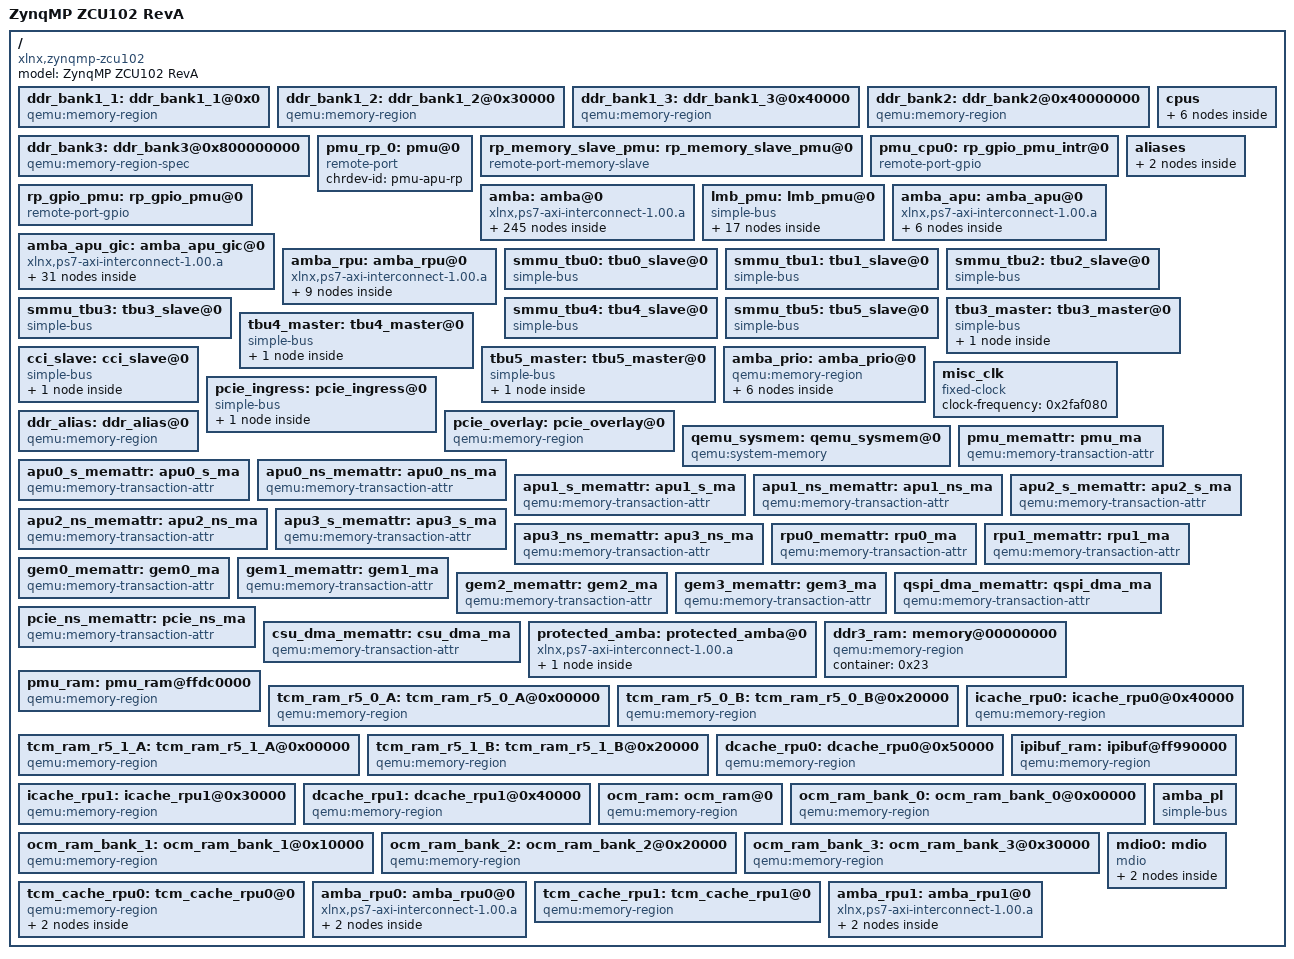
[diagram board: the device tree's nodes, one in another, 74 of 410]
/dts-v1/;

/ {
	#address-cells = < 0x02 >;
	#size-cells = < 0x01 >;
	model = "ZynqMP ZCU102 RevA";
	compatible = "xlnx,zynqmp-zcu102", "xlnx,zynqmp";

	ddr_bank1_1: ddr_bank1_1@0x0 {
		compatible = "qemu:memory-region";
		container = < 0x01 >;
		qemu,ram = < 0x02 >;
		reg = < 0x00 0x00 0x30000 >;
	};

	ddr_bank1_2: ddr_bank1_2@0x30000 {
		compatible = "qemu:memory-region";
		container = < 0x01 >;
		qemu,ram = < 0x02 >;
		reg = < 0x00 0x30000 0x10000 >;
		phandle = < 0x83 >;
	};

	ddr_bank1_3: ddr_bank1_3@0x40000 {
		compatible = "qemu:memory-region";
		container = < 0x01 >;
		qemu,ram = < 0x02 >;
		reg = < 0x00 0x40000 0x3ffc0000 >;
	};

	ddr_bank2: ddr_bank2@0x40000000 {
		compatible = "qemu:memory-region";
		container = < 0x01 >;
		qemu,ram = < 0x02 >;
		reg = < 0x00 0x40000000 0x40000000 >;
	};

	ddr_bank3: ddr_bank3@0x800000000 {
		compatible = "qemu:memory-region-spec";
		container = < 0x01 >;
		qemu,ram = < 0x02 >;
		reg = < 0x08 0x00 0x08 0x00 >;
	};

	pmu_rp_0: pmu@0 {
		compatible = "remote-port";
		#interrupt-cells = < 0x02 >;
		chrdev-id = "pmu-apu-rp";
		phandle = < 0x02 >;
	};

	rp_memory_slave_pmu: rp_memory_slave_pmu@0 {
		compatible = "remote-port-memory-slave";
		remote-ports = < 0x02 0x00 >;
		mr = < 0x03 >;
	};

	pmu_cpu0: rp_gpio_pmu_intr@0 {
		#interrupt-cells = < 0x01 >;
		compatible = "remote-port-gpio";
		remote-ports = < 0x02 0x01 >;
		interrupt-controller;
		num-gpios = < 0x01 >;
		phandle = < 0x61 >;
	};

	rp_gpio_pmu: rp_gpio_pmu@0 {
		compatible = "remote-port-gpio";
		remote-ports = < 0x02 0x02 >;
		gpio-controller;
		#gpio-cells = < 0x01 >;
		num-gpios = < 0x04 >;
		gpios = < 0x04 0x00 0x05 0x02 0x04 0x03 >;
		phandle = < 0x14 >;
	};

	amba: amba@0 {
		#interrupt-cells = < 0x01 >;
		compatible = "xlnx,ps7-axi-interconnect-1.00.a", "simple-bus";
		ranges;
		interrupt-map-mask = < 0x00 0x00 0xffff >;
		interrupt-map = < 0x00 0x00 0x08 0x06 0x00 0x08 0x04 >, < 0x00 0x00 0x09 0x06 0x00 0x09 0x04 >, < 0x00 0x00 0x0a 0x06 0x00 0x0a 0x04 >, < 0x00 0x00 0x0b 0x06 0x00 0x0b 0x04 >, < 0x00 0x00 0x0b 0x06 0x00 0x0b 0x04 >, < 0x00 0x00 0x0b 0x06 0x00 0x0b 0x04 >, < 0x00 0x00 0x0b 0x06 0x00 0x0b 0x04 >, < 0x00 0x00 0x0b 0x06 0x00 0x0b 0x04 >, < 0x00 0x00 0x0b 0x06 0x00 0x0b 0x04 >, < 0x00 0x00 0x0b 0x06 0x00 0x0b 0x04 >, < 0x00 0x00 0x0b 0x06 0x00 0x0b 0x04 >, < 0x00 0x00 0x0b 0x06 0x00 0x0b 0x04 >, < 0x00 0x00 0x0b 0x06 0x00 0x0b 0x04 >, < 0x00 0x00 0x0b 0x06 0x00 0x0b 0x04 >, < 0x00 0x00 0x0b 0x06 0x00 0x0b 0x04 >, < 0x00 0x00 0x0b 0x06 0x00 0x0b 0x04 >, < 0x00 0x00 0x0b 0x06 0x00 0x0b 0x04 >, < 0x00 0x00 0x0c 0x06 0x00 0x0c 0x04 >, < 0x00 0x00 0x0d 0x06 0x00 0x0d 0x04 >, < 0x00 0x00 0x0e 0x06 0x00 0x0e 0x04 >, < 0x00 0x00 0x0f 0x06 0x00 0x0f 0x04 >, < 0x00 0x00 0x10 0x06 0x00 0x10 0x04 >, < 0x00 0x00 0x11 0x06 0x00 0x11 0x04 >, < 0x00 0x00 0x12 0x06 0x00 0x12 0x04 >, < 0x00 0x00 0x13 0x06 0x00 0x13 0x04 >, < 0x00 0x00 0x14 0x06 0x00 0x14 0x04 >, < 0x00 0x00 0x15 0x06 0x00 0x15 0x04 >, < 0x00 0x00 0x16 0x06 0x00 0x16 0x04 >, < 0x00 0x00 0x17 0x06 0x00 0x17 0x04 >, < 0x00 0x00 0x18 0x06 0x00 0x18 0x04 >, < 0x00 0x00 0x19 0x06 0x00 0x19 0x04 >, < 0x00 0x00 0x19 0x06 0x00 0x19 0x04 >, < 0x00 0x00 0x1a 0x06 0x00 0x1a 0x04 >, < 0x00 0x00 0x1b 0x06 0x00 0x1b 0x04 >, < 0x00 0x00 0x1c 0x06 0x00 0x1c 0x04 >, < 0x00 0x00 0x1d 0x06 0x00 0x1d 0x04 >, < 0x00 0x00 0x1e 0x06 0x00 0x1e 0x04 >, < 0x00 0x00 0x1f 0x06 0x00 0x1f 0x04 >, < 0x00 0x00 0x20 0x06 0x00 0x20 0x04 >, < 0x00 0x00 0x21 0x06 0x00 0x21 0x04 >, < 0x00 0x00 0x22 0x06 0x00 0x22 0x04 >, < 0x00 0x00 0x23 0x06 0x00 0x23 0x04 >, < 0x00 0x00 0x24 0x06 0x00 0x24 0x04 >, < 0x00 0x00 0x25 0x06 0x00 0x25 0x04 >, < 0x00 0x00 0x26 0x06 0x00 0x26 0x04 >, < 0x00 0x00 0x27 0x06 0x00 0x27 0x04 >, < 0x00 0x00 0x28 0x06 0x00 0x28 0x04 >, < 0x00 0x00 0x29 0x06 0x00 0x29 0x04 >, < 0x00 0x00 0x2a 0x06 0x00 0x2a 0x04 >, < 0x00 0x00 0x2b 0x06 0x00 0x2b 0x04 >, < 0x00 0x00 0x2c 0x06 0x00 0x2c 0x04 >, < 0x00 0x00 0x2d 0x06 0x00 0x2d 0x04 >, < 0x00 0x00 0x2e 0x06 0x00 0x2e 0x04 >, < 0x00 0x00 0x2f 0x06 0x00 0x2f 0x04 >, < 0x00 0x00 0x30 0x06 0x00 0x30 0x04 >, < 0x00 0x00 0x31 0x06 0x00 0x31 0x04 >, < 0x00 0x00 0x32 0x06 0x00 0x32 0x04 >, < 0x00 0x00 0x33 0x06 0x00 0x33 0x04 >, < 0x00 0x00 0x34 0x06 0x00 0x34 0x04 >, < 0x00 0x00 0x35 0x06 0x00 0x35 0x04 >, < 0x00 0x00 0x36 0x06 0x00 0x36 0x04 >, < 0x00 0x00 0x37 0x06 0x00 0x37 0x04 >, < 0x00 0x00 0x38 0x06 0x00 0x38 0x04 >, < 0x00 0x00 0x39 0x06 0x00 0x39 0x04 >, < 0x00 0x00 0x3a 0x06 0x00 0x3a 0x04 >, < 0x00 0x00 0x3b 0x06 0x00 0x3b 0x04 >, < 0x00 0x00 0x3c 0x06 0x00 0x3c 0x04 >, < 0x00 0x00 0x3d 0x06 0x00 0x3d 0x04 >, < 0x00 0x00 0x3e 0x06 0x00 0x3e 0x04 >, < 0x00 0x00 0x3f 0x06 0x00 0x3f 0x04 >, < 0x00 0x00 0x40 0x06 0x00 0x40 0x04 >, < 0x00 0x00 0x41 0x06 0x00 0x41 0x04 >, < 0x00 0x00 0x42 0x06 0x00 0x42 0x04 >, < 0x00 0x00 0x43 0x06 0x00 0x43 0x04 >, < 0x00 0x00 0x44 0x06 0x00 0x44 0x04 >, < 0x00 0x00 0x45 0x06 0x00 0x45 0x04 >, < 0x00 0x00 0x46 0x06 0x00 0x46 0x04 >, < 0x00 0x00 0x47 0x06 0x00 0x47 0x04 >, < 0x00 0x00 0x48 0x06 0x00 0x48 0x04 >, < 0x00 0x00 0x49 0x06 0x00 0x49 0x04 >, < 0x00 0x00 0x4a 0x06 0x00 0x4a 0x04 >, < 0x00 0x00 0x4b 0x06 0x00 0x4b 0x04 >, < 0x00 0x00 0x4c 0x06 0x00 0x4c 0x04 >, < 0x00 0x00 0x4d 0x06 0x00 0x4d 0x04 >, < 0x00 0x00 0x4e 0x06 0x00 0x4e 0x04 >, < 0x00 0x00 0x4f 0x06 0x00 0x4f 0x04 >, < 0x00 0x00 0x50 0x06 0x00 0x50 0x04 >, < 0x00 0x00 0x51 0x06 0x00 0x51 0x04 >, < 0x00 0x00 0x52 0x06 0x00 0x52 0x04 >, < 0x00 0x00 0x53 0x06 0x00 0x53 0x04 >, < 0x00 0x00 0x54 0x06 0x00 0x54 0x04 >, < 0x00 0x00 0x55 0x06 0x00 0x55 0x04 >, < 0x00 0x00 0x56 0x06 0x00 0x56 0x04 >, < 0x00 0x00 0x57 0x06 0x00 0x57 0x04 >, < 0x00 0x00 0x58 0x06 0x00 0x58 0x04 >, < 0x00 0x00 0x58 0x06 0x00 0x58 0x04 >, < 0x00 0x00 0x59 0x06 0x00 0x59 0x04 >, < 0x00 0x00 0x5a 0x06 0x00 0x5a 0x04 >, < 0x00 0x00 0x5b 0x06 0x00 0x5b 0x04 >, < 0x00 0x00 0x5c 0x06 0x00 0x5c 0x04 >, < 0x00 0x00 0x5d 0x06 0x00 0x5d 0x04 >, < 0x00 0x00 0x5e 0x06 0x00 0x5e 0x04 >, < 0x00 0x00 0x5f 0x06 0x00 0x5f 0x04 >, < 0x00 0x00 0x60 0x06 0x00 0x60 0x04 >, < 0x00 0x00 0x68 0x06 0x00 0x68 0x04 >, < 0x00 0x00 0x69 0x06 0x00 0x69 0x04 >, < 0x00 0x00 0x6a 0x06 0x00 0x6a 0x04 >, < 0x00 0x00 0x6b 0x06 0x00 0x6b 0x04 >, < 0x00 0x00 0x6c 0x06 0x00 0x6c 0x04 >, < 0x00 0x00 0x6d 0x06 0x00 0x6d 0x04 >, < 0x00 0x00 0x6e 0x06 0x00 0x6e 0x04 >, < 0x00 0x00 0x6f 0x06 0x00 0x6f 0x04 >, < 0x00 0x00 0x70 0x06 0x00 0x70 0x04 >, < 0x00 0x00 0x71 0x06 0x00 0x71 0x04 >, < 0x00 0x00 0x72 0x06 0x00 0x72 0x04 >, < 0x00 0x00 0x73 0x06 0x00 0x73 0x04 >, < 0x00 0x00 0x74 0x06 0x00 0x74 0x04 >, < 0x00 0x00 0x75 0x06 0x00 0x75 0x04 >, < 0x00 0x00 0x76 0x06 0x00 0x76 0x04 >, < 0x00 0x00 0x77 0x06 0x00 0x77 0x04 >, < 0x00 0x00 0x78 0x06 0x00 0x78 0x04 >, < 0x00 0x00 0x78 0x06 0x00 0x78 0x04 >, < 0x00 0x00 0x78 0x06 0x00 0x78 0x04 >, < 0x00 0x00 0x78 0x06 0x00 0x78 0x04 >, < 0x00 0x00 0x78 0x06 0x00 0x78 0x04 >, < 0x00 0x00 0x78 0x06 0x00 0x78 0x04 >, < 0x00 0x00 0x78 0x06 0x00 0x78 0x04 >, < 0x00 0x00 0x78 0x06 0x00 0x78 0x04 >, < 0x00 0x00 0x78 0x06 0x00 0x78 0x04 >, < 0x00 0x00 0x78 0x06 0x00 0x78 0x04 >, < 0x00 0x00 0x78 0x06 0x00 0x78 0x04 >, < 0x00 0x00 0x79 0x06 0x00 0x79 0x04 >, < 0x00 0x00 0x7a 0x06 0x00 0x7a 0x04 >, < 0x00 0x00 0x7b 0x06 0x00 0x7b 0x04 >, < 0x00 0x00 0x7b 0x06 0x00 0x7b 0x04 >, < 0x00 0x00 0x7c 0x06 0x00 0x7c 0x04 >, < 0x00 0x00 0x7d 0x06 0x00 0x7d 0x04 >, < 0x00 0x00 0x7e 0x06 0x00 0x7e 0x04 >, < 0x00 0x00 0x7f 0x06 0x00 0x7f 0x04 >, < 0x00 0x00 0x80 0x06 0x00 0x80 0x04 >, < 0x00 0x00 0x81 0x06 0x00 0x81 0x04 >, < 0x00 0x00 0x82 0x06 0x00 0x82 0x04 >, < 0x00 0x00 0x83 0x06 0x00 0x83 0x04 >, < 0x00 0x00 0x84 0x06 0x00 0x84 0x04 >, < 0x00 0x00 0x85 0x06 0x00 0x85 0x04 >, < 0x00 0x00 0x86 0x06 0x00 0x86 0x04 >, < 0x00 0x00 0x86 0x06 0x00 0x86 0x04 >, < 0x00 0x00 0x86 0x06 0x00 0x86 0x04 >, < 0x00 0x00 0x86 0x06 0x00 0x86 0x04 >, < 0x00 0x00 0x86 0x06 0x00 0x86 0x04 >, < 0x00 0x00 0x86 0x06 0x00 0x86 0x04 >, < 0x00 0x00 0x86 0x06 0x00 0x86 0x04 >, < 0x00 0x00 0x87 0x06 0x00 0x87 0x04 >, < 0x00 0x00 0x88 0x06 0x00 0x88 0x04 >, < 0x00 0x00 0x89 0x06 0x00 0x89 0x04 >, < 0x00 0x00 0x8a 0x06 0x00 0x8a 0x04 >, < 0x00 0x00 0x8b 0x06 0x00 0x8b 0x04 >, < 0x00 0x00 0x8c 0x06 0x00 0x8c 0x04 >, < 0x00 0x00 0x8d 0x06 0x00 0x8d 0x04 >, < 0x00 0x00 0x8e 0x06 0x00 0x8e 0x04 >, < 0x00 0x00 0x8f 0x06 0x00 0x8f 0x04 >, < 0x00 0x00 0x90 0x06 0x00 0x90 0x04 >, < 0x00 0x00 0x91 0x06 0x00 0x91 0x04 >, < 0x00 0x00 0x92 0x06 0x00 0x92 0x04 >, < 0x00 0x00 0x93 0x06 0x00 0x93 0x04 >, < 0x00 0x00 0x94 0x06 0x00 0x94 0x04 >, < 0x00 0x00 0x95 0x06 0x00 0x95 0x04 >, < 0x00 0x00 0x96 0x06 0x00 0x96 0x04 >, < 0x00 0x00 0x97 0x06 0x00 0x97 0x04 >, < 0x00 0x00 0x98 0x06 0x00 0x98 0x04 >, < 0x00 0x00 0x99 0x06 0x00 0x99 0x04 >, < 0x00 0x00 0x9a 0x06 0x00 0x9a 0x04 >, < 0x00 0x00 0x9b 0x06 0x00 0x9b 0x04 >, < 0x00 0x00 0x08 0x07 0x00 0x08 0x04 >, < 0x00 0x00 0x09 0x07 0x00 0x09 0x04 >, < 0x00 0x00 0x0a 0x07 0x00 0x0a 0x04 >, < 0x00 0x00 0x0b 0x07 0x00 0x0b 0x04 >, < 0x00 0x00 0x0b 0x07 0x00 0x0b 0x04 >, < 0x00 0x00 0x0b 0x07 0x00 0x0b 0x04 >, < 0x00 0x00 0x0b 0x07 0x00 0x0b 0x04 >, < 0x00 0x00 0x0b 0x07 0x00 0x0b 0x04 >, < 0x00 0x00 0x0b 0x07 0x00 0x0b 0x04 >, < 0x00 0x00 0x0b 0x07 0x00 0x0b 0x04 >, < 0x00 0x00 0x0b 0x07 0x00 0x0b 0x04 >, < 0x00 0x00 0x0b 0x07 0x00 0x0b 0x04 >, < 0x00 0x00 0x0b 0x07 0x00 0x0b 0x04 >, < 0x00 0x00 0x0b 0x07 0x00 0x0b 0x04 >, < 0x00 0x00 0x0b 0x07 0x00 0x0b 0x04 >, < 0x00 0x00 0x0b 0x07 0x00 0x0b 0x04 >, < 0x00 0x00 0x0b 0x07 0x00 0x0b 0x04 >, < 0x00 0x00 0x0c 0x07 0x00 0x0c 0x04 >, < 0x00 0x00 0x0d 0x07 0x00 0x0d 0x04 >, < 0x00 0x00 0x0e 0x07 0x00 0x0e 0x04 >, < 0x00 0x00 0x0f 0x07 0x00 0x0f 0x04 >, < 0x00 0x00 0x10 0x07 0x00 0x10 0x04 >, < 0x00 0x00 0x11 0x07 0x00 0x11 0x04 >, < 0x00 0x00 0x12 0x07 0x00 0x12 0x04 >, < 0x00 0x00 0x13 0x07 0x00 0x13 0x04 >, < 0x00 0x00 0x14 0x07 0x00 0x14 0x04 >, < 0x00 0x00 0x15 0x07 0x00 0x15 0x04 >, < 0x00 0x00 0x16 0x07 0x00 0x16 0x04 >, < 0x00 0x00 0x17 0x07 0x00 0x17 0x04 >, < 0x00 0x00 0x18 0x07 0x00 0x18 0x04 >, < 0x00 0x00 0x19 0x07 0x00 0x19 0x04 >, < 0x00 0x00 0x19 0x07 0x00 0x19 0x04 >, < 0x00 0x00 0x1a 0x07 0x00 0x1a 0x04 >, < 0x00 0x00 0x1b 0x07 0x00 0x1b 0x04 >, < 0x00 0x00 0x1c 0x07 0x00 0x1c 0x04 >, < 0x00 0x00 0x1d 0x07 0x00 0x1d 0x04 >, < 0x00 0x00 0x1e 0x07 0x00 0x1e 0x04 >, < 0x00 0x00 0x1f 0x07 0x00 0x1f 0x04 >, < 0x00 0x00 0x20 0x07 0x00 0x20 0x04 >, < 0x00 0x00 0x21 0x07 0x00 0x21 0x04 >, < 0x00 0x00 0x22 0x07 0x00 0x22 0x04 >, < 0x00 0x00 0x23 0x07 0x00 0x23 0x04 >, < 0x00 0x00 0x24 0x07 0x00 0x24 0x04 >, < 0x00 0x00 0x25 0x07 0x00 0x25 0x04 >, < 0x00 0x00 0x26 0x07 0x00 0x26 0x04 >, < 0x00 0x00 0x27 0x07 0x00 0x27 0x04 >, < 0x00 0x00 0x28 0x07 0x00 0x28 0x04 >, < 0x00 0x00 0x29 0x07 0x00 0x29 0x04 >, < 0x00 0x00 0x2a 0x07 0x00 0x2a 0x04 >, < 0x00 0x00 0x2b 0x07 0x00 0x2b 0x04 >, < 0x00 0x00 0x2c 0x07 0x00 0x2c 0x04 >, < 0x00 0x00 0x2d 0x07 0x00 0x2d 0x04 >, < 0x00 0x00 0x2e 0x07 0x00 0x2e 0x04 >, < 0x00 0x00 0x2f 0x07 0x00 0x2f 0x04 >, < 0x00 0x00 0x30 0x07 0x00 0x30 0x04 >, < 0x00 0x00 0x31 0x07 0x00 0x31 0x04 >, < 0x00 0x00 0x32 0x07 0x00 0x32 0x04 >, < 0x00 0x00 0x33 0x07 0x00 0x33 0x04 >, < 0x00 0x00 0x34 0x07 0x00 0x34 0x04 >, < 0x00 0x00 0x35 0x07 0x00 0x35 0x04 >, < 0x00 0x00 0x36 0x07 0x00 0x36 0x04 >, < 0x00 0x00 0x37 0x07 0x00 0x37 0x04 >, < 0x00 0x00 0x38 0x07 0x00 0x38 0x04 >, < 0x00 0x00 0x39 0x07 0x00 0x39 0x04 >, < 0x00 0x00 0x3a 0x07 0x00 0x3a 0x04 >, < 0x00 0x00 0x3b 0x07 0x00 0x3b 0x04 >, < 0x00 0x00 0x3c 0x07 0x00 0x3c 0x04 >, < 0x00 0x00 0x3d 0x07 0x00 0x3d 0x04 >, < 0x00 0x00 0x3e 0x07 0x00 0x3e 0x04 >, < 0x00 0x00 0x3f 0x07 0x00 0x3f 0x04 >, < 0x00 0x00 0x40 0x07 0x00 0x40 0x04 >, < 0x00 0x00 0x41 0x07 0x00 0x41 0x04 >, < 0x00 0x00 0x42 0x07 0x00 0x42 0x04 >, < 0x00 0x00 0x43 0x07 0x00 0x43 0x04 >, < 0x00 0x00 0x44 0x07 0x00 0x44 0x04 >, < 0x00 0x00 0x45 0x07 0x00 0x45 0x04 >, < 0x00 0x00 0x46 0x07 0x00 0x46 0x04 >, < 0x00 0x00 0x47 0x07 0x00 0x47 0x04 >, < 0x00 0x00 0x48 0x07 0x00 0x48 0x04 >, < 0x00 0x00 0x49 0x07 0x00 0x49 0x04 >, < 0x00 0x00 0x4a 0x07 0x00 0x4a 0x04 >, < 0x00 0x00 0x4b 0x07 0x00 0x4b 0x04 >, < 0x00 0x00 0x4c 0x07 0x00 0x4c 0x04 >, < 0x00 0x00 0x4d 0x07 0x00 0x4d 0x04 >, < 0x00 0x00 0x4e 0x07 0x00 0x4e 0x04 >, < 0x00 0x00 0x4f 0x07 0x00 0x4f 0x04 >, < 0x00 0x00 0x50 0x07 0x00 0x50 0x04 >, < 0x00 0x00 0x51 0x07 0x00 0x51 0x04 >, < 0x00 0x00 0x52 0x07 0x00 0x52 0x04 >, < 0x00 0x00 0x53 0x07 0x00 0x53 0x04 >, < 0x00 0x00 0x54 0x07 0x00 0x54 0x04 >, < 0x00 0x00 0x55 0x07 0x00 0x55 0x04 >, < 0x00 0x00 0x56 0x07 0x00 0x56 0x04 >, < 0x00 0x00 0x57 0x07 0x00 0x57 0x04 >, < 0x00 0x00 0x58 0x07 0x00 0x58 0x04 >, < 0x00 0x00 0x58 0x07 0x00 0x58 0x04 >, < 0x00 0x00 0x59 0x07 0x00 0x59 0x04 >, < 0x00 0x00 0x5a 0x07 0x00 0x5a 0x04 >, < 0x00 0x00 0x5b 0x07 0x00 0x5b 0x04 >, < 0x00 0x00 0x5c 0x07 0x00 0x5c 0x04 >, < 0x00 0x00 0x5d 0x07 0x00 0x5d 0x04 >, < 0x00 0x00 0x5e 0x07 0x00 0x5e 0x04 >, < 0x00 0x00 0x5f 0x07 0x00 0x5f 0x04 >, < 0x00 0x00 0x60 0x07 0x00 0x60 0x04 >, < 0x00 0x00 0x68 0x07 0x00 0x68 0x04 >, < 0x00 0x00 0x69 0x07 0x00 0x69 0x04 >, < 0x00 0x00 0x6a 0x07 0x00 0x6a 0x04 >, < 0x00 0x00 0x6b 0x07 0x00 0x6b 0x04 >, < 0x00 0x00 0x6c 0x07 0x00 0x6c 0x04 >, < 0x00 0x00 0x6d 0x07 0x00 0x6d 0x04 >, < 0x00 0x00 0x6e 0x07 0x00 0x6e 0x04 >, < 0x00 0x00 0x6f 0x07 0x00 0x6f 0x04 >, < 0x00 0x00 0x70 0x07 0x00 0x70 0x04 >, < 0x00 0x00 0x71 0x07 0x00 0x71 0x04 >, < 0x00 0x00 0x72 0x07 0x00 0x72 0x04 >, < 0x00 0x00 0x73 0x07 0x00 0x73 0x04 >, < 0x00 0x00 0x74 0x07 0x00 0x74 0x04 >, < 0x00 0x00 0x75 0x07 0x00 0x75 0x04 >, < 0x00 0x00 0x76 0x07 0x00 0x76 0x04 >, < 0x00 0x00 0x77 0x07 0x00 0x77 0x04 >, < 0x00 0x00 0x78 0x07 0x00 0x78 0x04 >, < 0x00 0x00 0x78 0x07 0x00 0x78 0x04 >, < 0x00 0x00 0x78 0x07 0x00 0x78 0x04 >, < 0x00 0x00 0x78 0x07 0x00 0x78 0x04 >, < 0x00 0x00 0x78 0x07 0x00 0x78 0x04 >, < 0x00 0x00 0x78 0x07 0x00 0x78 0x04 >, < 0x00 0x00 0x78 0x07 0x00 0x78 0x04 >, < 0x00 0x00 0x78 0x07 0x00 0x78 0x04 >, < 0x00 0x00 0x78 0x07 0x00 0x78 0x04 >, < 0x00 0x00 0x78 0x07 0x00 0x78 0x04 >, < 0x00 0x00 0x78 0x07 0x00 0x78 0x04 >, < 0x00 0x00 0x79 0x07 0x00 0x79 0x04 >, < 0x00 0x00 0x7a 0x07 0x00 0x7a 0x04 >, < 0x00 0x00 0x7b 0x07 0x00 0x7b 0x04 >, < 0x00 0x00 0x7b 0x07 0x00 0x7b 0x04 >, < 0x00 0x00 0x7c 0x07 0x00 0x7c 0x04 >, < 0x00 0x00 0x7d 0x07 0x00 0x7d 0x04 >, < 0x00 0x00 0x7e 0x07 0x00 0x7e 0x04 >, < 0x00 0x00 0x7f 0x07 0x00 0x7f 0x04 >, < 0x00 0x00 0x80 0x07 0x00 0x80 0x04 >, < 0x00 0x00 0x81 0x07 0x00 0x81 0x04 >, < 0x00 0x00 0x82 0x07 0x00 0x82 0x04 >, < 0x00 0x00 0x83 0x07 0x00 0x83 0x04 >, < 0x00 0x00 0x84 0x07 0x00 0x84 0x04 >, < 0x00 0x00 0x85 0x07 0x00 0x85 0x04 >, < 0x00 0x00 0x86 0x07 0x00 0x86 0x04 >, < 0x00 0x00 0x86 0x07 0x00 0x86 0x04 >, < 0x00 0x00 0x86 0x07 0x00 0x86 0x04 >, < 0x00 0x00 0x86 0x07 0x00 0x86 0x04 >, < 0x00 0x00 0x86 0x07 0x00 0x86 0x04 >, < 0x00 0x00 0x86 0x07 0x00 0x86 0x04 >, < 0x00 0x00 0x86 0x07 0x00 0x86 0x04 >, < 0x00 0x00 0x87 0x07 0x00 0x87 0x04 >, < 0x00 0x00 0x88 0x07 0x00 0x88 0x04 >, < 0x00 0x00 0x89 0x07 0x00 0x89 0x04 >, < 0x00 0x00 0x8a 0x07 0x00 0x8a 0x04 >, < 0x00 0x00 0x8b 0x07 0x00 0x8b 0x04 >, < 0x00 0x00 0x8c 0x07 0x00 0x8c 0x04 >, < 0x00 0x00 0x8d 0x07 0x00 0x8d 0x04 >, < 0x00 0x00 0x8e 0x07 0x00 0x8e 0x04 >, < 0x00 0x00 0x8f 0x07 0x00 0x8f 0x04 >, < 0x00 0x00 0x90 0x07 0x00 0x90 0x04 >, < 0x00 0x00 0x91 0x07 0x00 0x91 0x04 >, < 0x00 0x00 0x92 0x07 0x00 0x92 0x04 >, < 0x00 0x00 0x93 0x07 0x00 0x93 0x04 >, < 0x00 0x00 0x94 0x07 0x00 0x94 0x04 >, < 0x00 0x00 0x95 0x07 0x00 0x95 0x04 >, < 0x00 0x00 0x96 0x07 0x00 0x96 0x04 >, < 0x00 0x00 0x97 0x07 0x00 0x97 0x04 >, < 0x00 0x00 0x98 0x07 0x00 0x98 0x04 >, < 0x00 0x00 0x99 0x07 0x00 0x99 0x04 >, < 0x00 0x00 0x9a 0x07 0x00 0x9a 0x04 >, < 0x00 0x00 0x9b 0x07 0x00 0x9b 0x04 >, < 0x00 0x00 0x08 0x08 0x00 0x08 0x04 >, < 0x00 0x00 0x09 0x08 0x00 0x09 0x04 >, < 0x00 0x00 0x0a 0x08 0x00 0x0a 0x04 >, < 0x00 0x00 0x0b 0x08 0x00 0x0b 0x04 >, < 0x00 0x00 0x0b 0x08 0x00 0x0b 0x04 >, < 0x00 0x00 0x0b 0x08 0x00 0x0b 0x04 >, < 0x00 0x00 0x0b 0x08 0x00 0x0b 0x04 >, < 0x00 0x00 0x0b 0x08 0x00 0x0b 0x04 >, < 0x00 0x00 0x0b 0x08 0x00 0x0b 0x04 >, < 0x00 0x00 0x0b 0x08 0x00 0x0b 0x04 >, < 0x00 0x00 0x0b 0x08 0x00 0x0b 0x04 >, < 0x00 0x00 0x0b 0x08 0x00 0x0b 0x04 >, < 0x00 0x00 0x0b 0x08 0x00 0x0b 0x04 >, < 0x00 0x00 0x0b 0x08 0x00 0x0b 0x04 >, < 0x00 0x00 0x0b 0x08 0x00 0x0b 0x04 >, < 0x00 0x00 0x0b 0x08 0x00 0x0b 0x04 >, < 0x00 0x00 0x0b 0x08 0x00 0x0b 0x04 >, < 0x00 0x00 0x0c 0x08 0x00 0x0c 0x04 >, < 0x00 0x00 0x0d 0x08 0x00 0x0d 0x04 >, < 0x00 0x00 0x0e 0x08 0x00 0x0e 0x04 >, < 0x00 0x00 0x0f 0x08 0x00 0x0f 0x04 >, < 0x00 0x00 0x10 0x08 0x00 0x10 0x04 >, < 0x00 0x00 0x11 0x08 0x00 0x11 0x04 >, < 0x00 0x00 0x12 0x08 0x00 0x12 0x04 >, < 0x00 0x00 0x13 0x08 0x00 0x13 0x04 >, < 0x00 0x00 0x14 0x08 0x00 0x14 0x04 >, < 0x00 0x00 0x15 0x08 0x00 0x15 0x04 >, < 0x00 0x00 0x16 0x08 0x00 0x16 0x04 >, < 0x00 0x00 0x17 0x08 0x00 0x17 0x04 >, < 0x00 0x00 0x18 0x08 0x00 0x18 0x04 >, < 0x00 0x00 0x19 0x08 0x00 0x19 0x04 >, < 0x00 0x00 0x19 0x08 0x00 0x19 0x04 >, < 0x00 0x00 0x1a 0x08 0x00 0x1a 0x04 >, < 0x00 0x00 0x1b 0x08 0x00 0x1b 0x04 >, < 0x00 0x00 0x1c 0x08 0x00 0x1c 0x04 >, < 0x00 0x00 0x1d 0x08 0x00 0x1d 0x04 >, < 0x00 0x00 0x1e 0x08 0x00 0x1e 0x04 >, < 0x00 0x00 0x1f 0x08 0x00 0x1f 0x04 >, < 0x00 0x00 0x20 0x08 0x00 0x20 0x04 >, < 0x00 0x00 0x21 0x08 0x00 0x21 0x04 >, < 0x00 0x00 0x22 0x08 0x00 0x22 0x04 >, < 0x00 0x00 0x23 0x08 0x00 0x23 0x04 >, < 0x00 0x00 0x24 0x08 0x00 0x24 0x04 >, < 0x00 0x00 0x25 0x08 0x00 0x25 0x04 >, < 0x00 0x00 0x26 0x08 0x00 0x26 0x04 >, < 0x00 0x00 0x27 0x08 0x00 0x27 0x04 >, < 0x00 0x00 0x28 0x08 0x00 0x28 0x04 >, < 0x00 0x00 0x29 0x08 0x00 0x29 0x04 >, < 0x00 0x00 0x2a 0x08 0x00 0x2a 0x04 >, < 0x00 0x00 0x2b 0x08 0x00 0x2b 0x04 >, < 0x00 0x00 0x2c 0x08 0x00 0x2c 0x04 >, < 0x00 0x00 0x2d 0x08 0x00 0x2d 0x04 >, < 0x00 0x00 0x2e 0x08 0x00 0x2e 0x04 >, < 0x00 0x00 0x2f 0x08 0x00 0x2f 0x04 >, < 0x00 0x00 0x30 0x08 0x00 0x30 0x04 >, < 0x00 0x00 0x31 0x08 0x00 0x31 0x04 >, < 0x00 0x00 0x32 0x08 0x00 0x32 0x04 >, < 0x00 0x00 0x33 0x08 0x00 0x33 0x04 >, < 0x00 0x00 0x34 0x08 0x00 0x34 0x04 >, < 0x00 0x00 0x35 0x08 0x00 0x35 0x04 >, < 0x00 0x00 0x36 0x08 0x00 0x36 0x04 >, < 0x00 0x00 0x37 0x08 0x00 0x37 0x04 >, < 0x00 0x00 0x38 0x08 0x00 0x38 0x04 >, < 0x00 0x00 0x39 0x08 0x00 0x39 0x04 >, < 0x00 0x00 0x3a 0x08 0x00 0x3a 0x04 >, < 0x00 0x00 0x3b 0x08 0x00 0x3b 0x04 >, < 0x00 0x00 0x3c 0x08 0x00 0x3c 0x04 >, < 0x00 0x00 0x3d 0x08 0x00 0x3d 0x04 >, < 0x00 0x00 0x3e 0x08 0x00 0x3e 0x04 >, < 0x00 0x00 0x3f 0x08 0x00 0x3f 0x04 >, < 0x00 0x00 0x40 0x08 0x00 0x40 0x04 >, < 0x00 0x00 0x41 0x08 0x00 0x41 0x04 >, < 0x00 0x00 0x42 0x08 0x00 0x42 0x04 >, < 0x00 0x00 0x43 0x08 0x00 0x43 0x04 >, < 0x00 0x00 0x44 0x08 0x00 0x44 0x04 >, < 0x00 0x00 0x45 0x08 0x00 0x45 0x04 >, < 0x00 0x00 0x46 0x08 0x00 0x46 0x04 >, < 0x00 0x00 0x47 0x08 0x00 0x47 0x04 >, < 0x00 0x00 0x48 0x08 0x00 0x48 0x04 >, < 0x00 0x00 0x49 0x08 0x00 0x49 0x04 >, < 0x00 0x00 0x4a 0x08 0x00 0x4a 0x04 >, < 0x00 0x00 0x4b 0x08 0x00 0x4b 0x04 >, < 0x00 0x00 0x4c 0x08 0x00 0x4c 0x04 >, < 0x00 0x00 0x4d 0x08 0x00 0x4d 0x04 >, < 0x00 0x00 0x4e 0x08 0x00 0x4e 0x04 >, < 0x00 0x00 0x4f 0x08 0x00 0x4f 0x04 >, < 0x00 0x00 0x50 0x08 0x00 0x50 0x04 >, < 0x00 0x00 0x51 0x08 0x00 0x51 0x04 >, < 0x00 0x00 0x52 0x08 0x00 0x52 0x04 >, < 0x00 0x00 0x53 0x08 0x00 0x53 0x04 >, < 0x00 0x00 0x54 0x08 0x00 0x54 0x04 >, < 0x00 0x00 0x55 0x08 0x00 0x55 0x04 >, < 0x00 0x00 0x56 0x08 0x00 0x56 0x04 >, < 0x00 0x00 0x57 0x08 0x00 0x57 0x04 >, < 0x00 0x00 0x58 0x08 0x00 0x58 0x04 >, < 0x00 0x00 0x58 0x08 0x00 0x58 0x04 >, < 0x00 0x00 0x59 0x08 0x00 0x59 0x04 >, < 0x00 0x00 0x5a 0x08 0x00 0x5a 0x04 >, < 0x00 0x00 0x5b 0x08 0x00 0x5b 0x04 >, < 0x00 0x00 0x5c 0x08 0x00 0x5c 0x04 >, < 0x00 0x00 0x5d 0x08 0x00 0x5d 0x04 >, < 0x00 0x00 0x5e 0x08 0x00 0x5e 0x04 >, < 0x00 0x00 0x5f 0x08 0x00 0x5f 0x04 >, < 0x00 0x00 0x60 0x08 0x00 0x60 0x04 >, < 0x00 0x00 0x68 0x08 0x00 0x68 0x04 >, < 0x00 0x00 0x69 0x08 0x00 0x69 0x04 >, < 0x00 0x00 0x6a 0x08 0x00 0x6a 0x04 >, < 0x00 0x00 0x6b 0x08 0x00 0x6b 0x04 >, < 0x00 0x00 0x6c 0x08 0x00 0x6c 0x04 >, < 0x00 0x00 0x6d 0x08 0x00 0x6d 0x04 >, < 0x00 0x00 0x6e 0x08 0x00 0x6e 0x04 >, < 0x00 0x00 0x6f 0x08 0x00 0x6f 0x04 >, < 0x00 0x00 0x70 0x08 0x00 0x70 0x04 >, < 0x00 0x00 0x71 0x08 0x00 0x71 0x04 >, < 0x00 0x00 0x72 0x08 0x00 0x72 0x04 >, < 0x00 0x00 0x73 0x08 0x00 0x73 0x04 >, < 0x00 0x00 0x74 0x08 0x00 0x74 0x04 >, < 0x00 0x00 0x75 0x08 0x00 0x75 0x04 >, < 0x00 0x00 0x76 0x08 0x00 0x76 0x04 >, < 0x00 0x00 0x77 0x08 0x00 0x77 0x04 >, < 0x00 0x00 0x78 0x08 0x00 0x78 0x04 >, < 0x00 0x00 0x78 0x08 0x00 0x78 0x04 >, < 0x00 0x00 0x78 0x08 0x00 0x78 0x04 >, < 0x00 0x00 0x78 0x08 0x00 0x78 0x04 >, < 0x00 0x00 0x78 0x08 0x00 0x78 0x04 >, < 0x00 0x00 0x78 0x08 0x00 0x78 0x04 >, < 0x00 0x00 0x78 0x08 0x00 0x78 0x04 >, < 0x00 0x00 0x78 0x08 0x00 0x78 0x04 >, < 0x00 0x00 0x78 0x08 0x00 0x78 0x04 >, < 0x00 0x00 0x78 0x08 0x00 0x78 0x04 >, < 0x00 0x00 0x78 0x08 0x00 0x78 0x04 >, < 0x00 0x00 0x79 0x08 0x00 0x79 0x04 >, < 0x00 0x00 0x7a 0x08 0x00 0x7a 0x04 >, < 0x00 0x00 0x7b 0x08 0x00 0x7b 0x04 >, < 0x00 0x00 0x7b 0x08 0x00 0x7b 0x04 >, < 0x00 0x00 0x7c 0x08 0x00 0x7c 0x04 >, < 0x00 0x00 0x7d 0x08 0x00 0x7d 0x04 >, < 0x00 0x00 0x7e 0x08 0x00 0x7e 0x04 >, < 0x00 0x00 0x7f 0x08 0x00 0x7f 0x04 >, < 0x00 0x00 0x80 0x08 0x00 0x80 0x04 >, < 0x00 0x00 0x81 0x08 0x00 0x81 0x04 >, < 0x00 0x00 0x82 0x08 0x00 0x82 0x04 >, < 0x00 0x00 0x83 0x08 0x00 0x83 0x04 >, < 0x00 0x00 0x84 0x08 0x00 0x84 0x04 >, < 0x00 0x00 0x85 0x08 0x00 0x85 0x04 >, < 0x00 0x00 0x86 0x08 0x00 0x86 0x04 >, < 0x00 0x00 0x86 0x08 0x00 0x86 0x04 >, < 0x00 0x00 0x86 0x08 0x00 0x86 0x04 >, < 0x00 0x00 0x86 0x08 0x00 0x86 0x04 >, < 0x00 0x00 0x86 0x08 0x00 0x86 0x04 >, < 0x00 0x00 0x86 0x08 0x00 0x86 0x04 >, < 0x00 0x00 0x86 0x08 0x00 0x86 0x04 >, < 0x00 0x00 0x87 0x08 0x00 0x87 0x04 >, < 0x00 0x00 0x88 0x08 0x00 0x88 0x04 >, < 0x00 0x00 0x89 0x08 0x00 0x89 0x04 >, < 0x00 0x00 0x8a 0x08 0x00 0x8a 0x04 >, < 0x00 0x00 0x8b 0x08 0x00 0x8b 0x04 >, < 0x00 0x00 0x8c 0x08 0x00 0x8c 0x04 >, < 0x00 0x00 0x8d 0x08 0x00 0x8d 0x04 >, < 0x00 0x00 0x8e 0x08 0x00 0x8e 0x04 >, < 0x00 0x00 0x8f 0x08 0x00 0x8f 0x04 >, < 0x00 0x00 0x90 0x08 0x00 0x90 0x04 >, < 0x00 0x00 0x91 0x08 0x00 0x91 0x04 >, < 0x00 0x00 0x92 0x08 0x00 0x92 0x04 >, < 0x00 0x00 0x93 0x08 0x00 0x93 0x04 >, < 0x00 0x00 0x94 0x08 0x00 0x94 0x04 >, < 0x00 0x00 0x95 0x08 0x00 0x95 0x04 >, < 0x00 0x00 0x96 0x08 0x00 0x96 0x04 >, < 0x00 0x00 0x97 0x08 0x00 0x97 0x04 >, < 0x00 0x00 0x98 0x08 0x00 0x98 0x04 >, < 0x00 0x00 0x99 0x08 0x00 0x99 0x04 >, < 0x00 0x00 0x9a 0x08 0x00 0x9a 0x04 >, < 0x00 0x00 0x9b 0x08 0x00 0x9b 0x04 >;
		#address-cells = < 0x02 >;
		#size-cells = < 0x01 >;
		phandle = < 0x23 >;

		apu: apu@0xFD5C0000 {
			compatible = "xlnx,apu";
			#gpio-cells = < 0x01 >;
			reg = < 0x00 0xfd5c0000 0x1000 >;
			cpu0 = < 0x09 >;
			cpu1 = < 0x0a >;
			cpu2 = < 0x0b >;
			cpu3 = < 0x0c >;
			gpios = < 0x0d 0x01 0x00 0x0d 0x02 0x00 0x0d 0x03 0x00 0x0d 0x04 0x00 >;
			phandle = < 0x67 >;
		};

		rpu_ctrl: rpu_control@0xFF9A0000 {
			#gpio-cells = < 0x01 >;
			compatible = "xlnx,rpu-control";
			reg = < 0x00 0xff9a0000 0x400 >;
			gpio-controller;
			atcm1-for-rpu0 = < 0x0e >;
			btcm1-for-rpu0 = < 0x0f >;
			icache-for-rpu1 = < 0x10 >;
			dcache-for-rpu1 = < 0x11 >;
			gic-for-rpu = < 0x07 >;
			gpios = < 0x04 0x06 0x04 0x07 0x0d 0x05 0x0d 0x06 >;
			ddr-mem-for-rpu = < 0x12 >;
			phandle = < 0x71 >;
		};

		pmu_global: pmu_global@0xFFD80000 {
			interrupt-parent = < 0x13 >;
			interrupts = < 0x17 0x00 >, < 0x18 0x00 >, < 0x1a 0x00 >, < 0x1b 0x00 >, < 0x1c 0x00 >, < 0x1d 0x00 >;
			compatible = "xlnx,pmu_global";
			reg = < 0x00 0xffd80000 0x40000 >;
			gpio-controller;
			#gpio-cells = < 0x01 >;
			num-gpios = < 0x1a >;
			gpios = < 0x14 0x03 >;
			gpio-names = "mb_sleep";
			error-out-gpios = < 0x15 0x1d 0x00 0x15 0x1e 0x00 >;
			pwr-state-gpios = < 0x16 0x01 0x16 0x02 0x16 0x03 0x16 0x04 0x16 0x05 0x16 0x06 0x17 0x00 0x16 0x0a 0x17 0x01 0x17 0x02 0x16 0x09 0x16 0x09 0x16 0x14 0x16 0x15 0x16 0x16 0x16 0x17 0x16 0x0c 0x16 0x0d 0x16 0x0e 0x16 0x0f 0x16 0x07 0x16 0x08 0x16 0x1c >;
			phandle = < 0x04 >;
		};

		apu_ipi: apu_ipi@0xFF300000 {
			compatible = "xlnx,zynqmp_ipi";
			gpio-controller;
			#gpio-cells = < 0x02 >;
			interrupts = < 0x00 >;
			interrupt-map = < 0x00 0x00 0x00 0x08 0x00 0x23 0x04 >, < 0x00 0x00 0x00 0x06 0x00 0x23 0x04 >, < 0x00 0x00 0x00 0x07 0x00 0x23 0x04 >;
			interrupt-map-mask = < 0x00 0x00 0x00 0x00 >;
			reg = < 0x00 0xff300000 0x1000 >;
			num-gpios = < 0x40 >;
			interrupt-gpios = < 0x18 0x00 0x00 0x19 0x00 0x00 0x1a 0x00 0x00 0x1b 0x00 0x00 0x1c 0x00 0x00 0x1d 0x00 0x00 0x1e 0x00 0x00 0x1f 0x00 0x00 0x20 0x00 0x00 0x21 0x00 0x00 0x22 0x00 0x00 >;
			gpios = < 0x18 0x20 0x00 0x19 0x20 0x00 0x1a 0x20 0x00 0x1b 0x20 0x00 0x1c 0x20 0x00 0x1d 0x20 0x00 0x1e 0x20 0x00 0x1f 0x20 0x00 0x20 0x20 0x00 0x21 0x20 0x00 0x22 0x20 0x00 >;
			phandle = < 0x18 >;
		};

		rpu_0_ipi: rpu_0_ipi@0xFF310000 {
			compatible = "xlnx,zynqmp_ipi";
			gpio-controller;
			#gpio-cells = < 0x02 >;
			interrupts = < 0x00 >;
			interrupt-map = < 0x00 0x00 0x00 0x08 0x00 0x21 0x04 >, < 0x00 0x00 0x00 0x06 0x00 0x21 0x04 >, < 0x00 0x00 0x00 0x07 0x00 0x21 0x04 >;
			interrupt-map-mask = < 0x00 0x00 0x00 0x00 >;
			reg = < 0x00 0xff310000 0x1000 >;
			num-gpios = < 0x40 >;
			interrupt-gpios = < 0x18 0x08 0x00 0x19 0x08 0x00 0x1a 0x08 0x00 0x1b 0x08 0x00 0x1c 0x08 0x00 0x1d 0x08 0x00 0x1e 0x08 0x00 0x1f 0x08 0x00 0x20 0x08 0x00 0x21 0x08 0x00 0x22 0x08 0x00 >;
			gpios = < 0x18 0x28 0x00 0x19 0x28 0x00 0x1a 0x28 0x00 0x1b 0x28 0x00 0x1c 0x28 0x00 0x1d 0x28 0x00 0x1e 0x28 0x00 0x1f 0x28 0x00 0x20 0x28 0x00 0x21 0x28 0x00 0x22 0x28 0x00 >;
			phandle = < 0x19 >;
		};

		rpu_1_ipi: rpu_1_ipi@0xFF320000 {
			compatible = "xlnx,zynqmp_ipi";
			gpio-controller;
			#gpio-cells = < 0x02 >;
			interrupts = < 0x00 >;
			interrupt-map = < 0x00 0x00 0x00 0x08 0x00 0x22 0x04 >, < 0x00 0x00 0x00 0x06 0x00 0x22 0x04 >, < 0x00 0x00 0x00 0x07 0x00 0x22 0x04 >;
			interrupt-map-mask = < 0x00 0x00 0x00 0x00 >;
			reg = < 0x00 0xff320000 0x1000 >;
			num-gpios = < 0x40 >;
			interrupt-gpios = < 0x18 0x09 0x00 0x19 0x09 0x00 0x1a 0x09 0x00 0x1b 0x09 0x00 0x1c 0x09 0x00 0x1d 0x09 0x00 0x1e 0x09 0x00 0x1f 0x09 0x00 0x20 0x09 0x00 0x21 0x09 0x00 0x22 0x09 0x00 >;
			gpios = < 0x18 0x29 0x00 0x19 0x29 0x00 0x1a 0x29 0x00 0x1b 0x29 0x00 0x1c 0x29 0x00 0x1d 0x29 0x00 0x1e 0x29 0x00 0x1f 0x29 0x00 0x20 0x29 0x00 0x21 0x29 0x00 0x22 0x29 0x00 >;
			phandle = < 0x1a >;
		};

		pmu_0_ipi: pmu_0_ipi@0xFF330000 {
			compatible = "xlnx,zynqmp_ipi";
			gpio-controller;
			#gpio-cells = < 0x02 >;
			interrupt-parent = < 0x13 >;
			interrupts = < 0x13 0x00 >;
			reg = < 0x00 0xff330000 0x1000 >;
			num-gpios = < 0x40 >;
			interrupt-gpios = < 0x18 0x10 0x00 0x19 0x10 0x00 0x1a 0x10 0x00 0x1b 0x10 0x00 0x1c 0x10 0x00 0x1d 0x10 0x00 0x1e 0x10 0x00 0x1f 0x10 0x00 0x20 0x10 0x00 0x21 0x10 0x00 0x22 0x10 0x00 >;
			gpios = < 0x18 0x30 0x00 0x19 0x30 0x00 0x1a 0x30 0x00 0x1b 0x30 0x00 0x1c 0x30 0x00 0x1d 0x30 0x00 0x1e 0x30 0x00 0x1f 0x30 0x00 0x20 0x30 0x00 0x21 0x30 0x00 0x22 0x30 0x00 >;
			phandle = < 0x1b >;
		};

		pmu_1_ipi: pmu_1_ipi@0xFF331000 {
			compatible = "xlnx,zynqmp_ipi";
			gpio-controller;
			#gpio-cells = < 0x02 >;
			interrupt-parent = < 0x13 >;
			interrupts = < 0x14 0x00 >;
			reg = < 0x00 0xff331000 0x1000 >;
			num-gpios = < 0x40 >;
			interrupt-gpios = < 0x18 0x11 0x00 0x19 0x11 0x00 0x1a 0x11 0x00 0x1b 0x11 0x00 0x1c 0x11 0x00 0x1d 0x11 0x00 0x1e 0x11 0x00 0x1f 0x11 0x00 0x20 0x11 0x00 0x21 0x11 0x00 0x22 0x11 0x00 >;
			gpios = < 0x18 0x31 0x00 0x19 0x31 0x00 0x1a 0x31 0x00 0x1b 0x31 0x00 0x1c 0x31 0x00 0x1d 0x31 0x00 0x1e 0x31 0x00 0x1f 0x31 0x00 0x20 0x31 0x00 0x21 0x31 0x00 0x22 0x31 0x00 >;
			phandle = < 0x1c >;
		};

		pmu_2_ipi: pmu_2_ipi@0xFF332000 {
			compatible = "xlnx,zynqmp_ipi";
			gpio-controller;
			#gpio-cells = < 0x02 >;
			interrupt-parent = < 0x13 >;
			interrupts = < 0x15 0x00 >;
			reg = < 0x00 0xff332000 0x1000 >;
			num-gpios = < 0x40 >;
			interrupt-gpios = < 0x18 0x12 0x00 0x19 0x12 0x00 0x1a 0x12 0x00 0x1b 0x12 0x00 0x1c 0x12 0x00 0x1d 0x12 0x00 0x1e 0x12 0x00 0x1f 0x12 0x00 0x20 0x12 0x00 0x21 0x12 0x00 0x22 0x12 0x00 >;
			gpios = < 0x18 0x32 0x00 0x19 0x32 0x00 0x1a 0x32 0x00 0x1b 0x32 0x00 0x1c 0x32 0x00 0x1d 0x32 0x00 0x1e 0x32 0x00 0x1f 0x32 0x00 0x20 0x32 0x00 0x21 0x32 0x00 0x22 0x32 0x00 >;
			phandle = < 0x1d >;
		};

		pmu_3_ipi: pmu_3_ipi@0xFF333000 {
			compatible = "xlnx,zynqmp_ipi";
			gpio-controller;
			#gpio-cells = < 0x02 >;
			interrupt-parent = < 0x13 >;
			interrupts = < 0x16 0x00 >;
			reg = < 0x00 0xff333000 0x1000 >;
			num-gpios = < 0x40 >;
			interrupt-gpios = < 0x18 0x13 0x00 0x19 0x13 0x00 0x1a 0x13 0x00 0x1b 0x13 0x00 0x1c 0x13 0x00 0x1d 0x13 0x00 0x1e 0x13 0x00 0x1f 0x13 0x00 0x20 0x13 0x00 0x21 0x13 0x00 0x22 0x13 0x00 >;
			gpios = < 0x18 0x33 0x00 0x19 0x33 0x00 0x1a 0x33 0x00 0x1b 0x33 0x00 0x1c 0x33 0x00 0x1d 0x33 0x00 0x1e 0x33 0x00 0x1f 0x33 0x00 0x20 0x33 0x00 0x21 0x33 0x00 0x22 0x33 0x00 >;
			phandle = < 0x1e >;
		};

		pl_0_ipi: pl_0_ipi@0xFF340000 {
			compatible = "xlnx,zynqmp_ipi";
			gpio-controller;
			#gpio-cells = < 0x02 >;
			interrupts = < 0x00 >;
			interrupt-map = < 0x00 0x00 0x00 0x08 0x00 0x1d 0x04 >, < 0x00 0x00 0x00 0x06 0x00 0x1d 0x04 >, < 0x00 0x00 0x00 0x07 0x00 0x1d 0x04 >;
			interrupt-map-mask = < 0x00 0x00 0x00 0x00 >;
			reg = < 0x00 0xff340000 0x1000 >;
			num-gpios = < 0x40 >;
			interrupt-gpios = < 0x18 0x18 0x00 0x19 0x18 0x00 0x1a 0x18 0x00 0x1b 0x18 0x00 0x1c 0x18 0x00 0x1d 0x18 0x00 0x1e 0x18 0x00 0x1f 0x18 0x00 0x20 0x18 0x00 0x21 0x18 0x00 0x22 0x18 0x00 >;
			gpios = < 0x18 0x34 0x00 0x19 0x34 0x00 0x1a 0x34 0x00 0x1b 0x34 0x00 0x1c 0x34 0x00 0x1d 0x34 0x00 0x1e 0x34 0x00 0x1f 0x34 0x00 0x20 0x34 0x00 0x21 0x34 0x00 0x22 0x34 0x00 >;
			phandle = < 0x1f >;
		};

		pl_1_ipi: pl_1_ipi@0xFF350000 {
			compatible = "xlnx,zynqmp_ipi";
			gpio-controller;
			#gpio-cells = < 0x02 >;
			interrupts = < 0x00 >;
			interrupt-map = < 0x00 0x00 0x00 0x08 0x00 0x1e 0x04 >, < 0x00 0x00 0x00 0x06 0x00 0x1e 0x04 >, < 0x00 0x00 0x00 0x07 0x00 0x1e 0x04 >;
			interrupt-map-mask = < 0x00 0x00 0x00 0x00 >;
			reg = < 0x00 0xff350000 0x1000 >;
			num-gpios = < 0x40 >;
			interrupt-gpios = < 0x18 0x19 0x00 0x19 0x19 0x00 0x1a 0x19 0x00 0x1b 0x19 0x00 0x1c 0x19 0x00 0x1d 0x19 0x00 0x1e 0x19 0x00 0x1f 0x19 0x00 0x20 0x19 0x00 0x21 0x19 0x00 0x22 0x19 0x00 >;
			gpios = < 0x18 0x35 0x00 0x19 0x35 0x00 0x1a 0x35 0x00 0x1b 0x35 0x00 0x1c 0x35 0x00 0x1d 0x35 0x00 0x1e 0x35 0x00 0x1f 0x35 0x00 0x20 0x35 0x00 0x21 0x35 0x00 0x22 0x35 0x00 >;
			phandle = < 0x20 >;
		};

		pl_2_ipi: pl_2_ipi@0xFF360000 {
			compatible = "xlnx,zynqmp_ipi";
			gpio-controller;
			#gpio-cells = < 0x02 >;
			interrupts = < 0x00 >;
			interrupt-map = < 0x00 0x00 0x00 0x08 0x00 0x1f 0x04 >, < 0x00 0x00 0x00 0x06 0x00 0x1f 0x04 >, < 0x00 0x00 0x00 0x07 0x00 0x1f 0x04 >;
			interrupt-map-mask = < 0x00 0x00 0x00 0x00 >;
			reg = < 0x00 0xff360000 0x1000 >;
			num-gpios = < 0x40 >;
			interrupt-gpios = < 0x18 0x1a 0x00 0x19 0x1a 0x00 0x1a 0x1a 0x00 0x1b 0x1a 0x00 0x1c 0x1a 0x00 0x1d 0x1a 0x00 0x1e 0x1a 0x00 0x1f 0x1a 0x00 0x20 0x1a 0x00 0x21 0x1a 0x00 0x22 0x1a 0x00 >;
			gpios = < 0x18 0x36 0x00 0x19 0x36 0x00 0x1a 0x36 0x00 0x1b 0x36 0x00 0x1c 0x36 0x00 0x1d 0x36 0x00 0x1e 0x36 0x00 0x1f 0x36 0x00 0x20 0x36 0x00 0x21 0x36 0x00 0x22 0x36 0x00 >;
			phandle = < 0x21 >;
		};

		pl_3_ipi: pl_3_ipi@0xFF370000 {
			compatible = "xlnx,zynqmp_ipi";
			gpio-controller;
			#gpio-cells = < 0x02 >;
			interrupts = < 0x00 >;
			interrupt-map = < 0x00 0x00 0x00 0x08 0x00 0x20 0x04 >, < 0x00 0x00 0x00 0x06 0x00 0x20 0x04 >, < 0x00 0x00 0x00 0x07 0x00 0x20 0x04 >;
			interrupt-map-mask = < 0x00 0x00 0x00 0x00 >;
			reg = < 0x00 0xff370000 0x1000 >;
			num-gpios = < 0x40 >;
			interrupt-gpios = < 0x18 0x1b 0x00 0x19 0x1b 0x00 0x1a 0x1b 0x00 0x1b 0x1b 0x00 0x1c 0x1b 0x00 0x1d 0x1b 0x00 0x1e 0x1b 0x00 0x1f 0x1b 0x00 0x20 0x1b 0x00 0x21 0x1b 0x00 0x22 0x1b 0x00 >;
			gpios = < 0x18 0x37 0x00 0x19 0x37 0x00 0x1a 0x37 0x00 0x1b 0x37 0x00 0x1c 0x37 0x00 0x1d 0x37 0x00 0x1e 0x37 0x00 0x1f 0x37 0x00 0x20 0x37 0x00 0x21 0x37 0x00 0x22 0x37 0x00 >;
			phandle = < 0x22 >;
		};

		xlnx_zynqmp_csu_core: csu_core {
			compatible = "xlnx,zynqmp-csu-core";
			reg = < 0x00 0xffca0000 0x100 >;
		};

		lpd_slcr_0: zynqmp_lpd_slcr@0xFF410000 {
			compatible = "xlnx,lpd-slcr";
			reg = < 0x00 0xff410000 0x9000 >;
			gic-for-rpu = < 0x07 >;
			gic-for-apu = < 0x06 >;
		};

		lpd_slcr_secure: zynqmp_lpd_slcr_secure@0xFF4B0000 {
			compatible = "xlnx.lpd-slcr-secure";
			reg = < 0x00 0xff4b0000 0x38 >;
		};

		xppu: xppu@0 {
			compatible = "xlnx,xppu";
			reg-extended = < 0x23 0x00 0xff980000 0x10000 0x24 0x00 0xff990000 0x00 0x1000 0x03 0x24 0x00 0xff000000 0x00 0xfc0000 0x02 0x24 0x00 0xfe000000 0x00 0x1000000 0x02 0x24 0x00 0xc0000000 0x00 0x20000000 0x02 >;
			mr = < 0x23 >;
			interrupts = < 0x58 >;
		};

		smmu0: smmu0@0xFD800000 {
			compatible = "arm,mmu-500";
			reg-extended = < 0x23 0x00 0xfd800000 0x10000 0x25 0x00 0x00 0xffffffff 0xffffffff 0x26 0x00 0x00 0xffffffff 0xffffffff 0x27 0x00 0x00 0xffffffff 0xffffffff 0x28 0x00 0x00 0xffffffff 0xffffffff 0x29 0x00 0x00 0xffffffff 0xffffffff 0x2a 0x00 0x00 0xffffffff 0xffffffff >;
			interrupt-parent = < 0x2b >;
			interrupts = < 0x00 0x01 0x02 0x03 0x04 0x05 0x06 0x07 0x08 0x08 0x09 0x0a 0x0b 0x0c 0x0d 0x0e 0x0f 0x10 0x11 >;
			dma = < 0x2c >;
			mr-0 = < 0x2c >;
			mr-1 = < 0x2c >;
			mr-2 = < 0x2c >;
			mr-3 = < 0x2d >;
			mr-4 = < 0x2e >;
			mr-5 = < 0x2f >;
		};

		smmu_reg: smmu0@0xFD5F0000 {
			compatible = "xlnx,smmu-reg";
			reg = < 0x00 0xfd5f0000 0x1000 >;
			interrupt-controller;
			interrupts = < 0x9b >;
			phandle = < 0x2b >;
		};

		cci_mem1: cci_mem1@0 {
			#address-cells = < 0x02 >;
			#size-cells = < 0x02 >;
			#priority-cells = < 0x01 >;
			compatible = "simple-bus";
			ranges;
			phandle = < 0x30 >;
		};

		cci_mem2: cci_mem2@0 {
			#address-cells = < 0x02 >;
			#size-cells = < 0x02 >;
			#priority-cells = < 0x01 >;
			compatible = "simple-bus";
			ranges;
			phandle = < 0x31 >;
		};

		cci: cci@0xFD6E0000 {
			compatible = "arm,cci-400";
			gpio-controller;
			#gpio-cells = < 0x01 >;
			reg-extended = < 0x23 0x00 0xfd6e0000 0xf000 0x2c 0x00 0x00 0xffffffff 0xffffffff 0x02 >;
			M0 = < 0x24 >;
			M1 = < 0x30 >;
			M2 = < 0x31 >;
			phandle = < 0x34 >;
		};

		ocm_xmpu: ocm_xmpu@0xFFA70000 {
			compatible = "xlnx,xmpu";
			interrupts = < 0x58 >;
			reg-extended = < 0x23 0x00 0xffa70000 0x1000 0x23 0x00 0xfffc0000 0x40000 >;
			protected-mr = < 0x32 >;
			mr-0 = < 0x23 >;
			protected-base = < 0xfffc0000 >;
		};

		ddr_xmpu0: ddr_xmpu0_@_DDR_XMPU0_CFG {
			compatible = "xlnx,xmpu";
			interrupts = < 0x86 >;
			reg-extended = < 0x23 0x00 0xfd000000 0x1000 0x33 0x00 0x00 0x00 0x80000000 0x00 >;
			align = < 0x01 >;
			protected-mr = < 0x01 >;
			protected-base = < 0x00 >;
			mr-0 = < 0x33 >;
		};

		ddr_xmpu1: ddr_xmpu1_@_DDR_XMPU1_CFG {
			compatible = "xlnx,xmpu";
			interrupts = < 0x86 >;
			reg-extended = < 0x23 0x00 0xfd010000 0x1000 0x30 0x00 0x00 0x00 0x80000000 0x00 >;
			align = < 0x01 >;
			protected-mr = < 0x01 >;
			protected-base = < 0x00 >;
			mr-0 = < 0x30 >;
			gpios = < 0x34 0x00 >;
		};

		ddr_xmpu2: ddr_xmpu2_@_DDR_XMPU2_CFG {
			compatible = "xlnx,xmpu";
			interrupts = < 0x86 >;
			reg-extended = < 0x23 0x00 0xfd020000 0x1000 0x31 0x00 0x00 0x00 0x80000000 0x00 >;
			align = < 0x01 >;
			protected-mr = < 0x01 >;
			protected-base = < 0x00 >;
			mr-0 = < 0x31 >;
			gpios = < 0x34 0x01 >;
		};

		ddr_xmpu3: ddr_xmpu3_@_DDR_XMPU3_CFG {
			compatible = "xlnx,xmpu";
			interrupts = < 0x86 >;
			reg-extended = < 0x23 0x00 0xfd030000 0x1000 0x2d 0x00 0x00 0x00 0x80000000 0x00 >;
			align = < 0x01 >;
			protected-mr = < 0x01 >;
			protected-base = < 0x00 >;
			mr-0 = < 0x2d >;
		};

		ddr_xmpu4: ddr_xmpu4_@_DDR_XMPU4_CFG {
			compatible = "xlnx,xmpu";
			interrupts = < 0x86 >;
			reg-extended = < 0x23 0x00 0xfd040000 0x1000 0x2e 0x00 0x00 0x00 0x80000000 0x00 >;
			align = < 0x01 >;
			protected-mr = < 0x01 >;
			protected-base = < 0x00 >;
			mr-0 = < 0x2e >;
		};

		ddr_xmpu5: ddr_xmpu5_@_DDR_XMPU5_CFG {
			compatible = "xlnx,xmpu";
			interrupts = < 0x86 >;
			reg-extended = < 0x23 0x00 0xfd050000 0x1000 0x2f 0x00 0x00 0x00 0x80000000 0x00 >;
			align = < 0x01 >;
			protected-mr = < 0x01 >;
			protected-base = < 0x00 >;
			mr-0 = < 0x2f >;
		};

		downstream_amba_priority_bus {
			compatible = "qemu:memory-region";
			alias = < 0x35 >;
			reg = < 0x00 0x00 0xffffffff >;
			priority = < 0xffffffff >;
		};

		ps7_afi_0: ps7-afi@0xFD360000 {
			compatible = "xlnx,ps7-afi-1.00.a";
			reg = < 0x00 0xfd360000 0x1000 >;
		};

		ps7_afi_1: ps7-afi@0xFD370000 {
			compatible = "xlnx,ps7-afi-1.00.a";
			reg = < 0x00 0xfd370000 0x1000 >;
		};

		ps7_afi_2: ps7-afi@0xFD380000 {
			compatible = "xlnx,ps7-afi-1.00.a";
			reg = < 0x00 0xfd380000 0x1000 >;
		};

		ps7_afi_3: ps7-afi@0xFD390000 {
			compatible = "xlnx,ps7-afi-1.00.a";
			reg = < 0x00 0xfd390000 0x1000 >;
		};

		ps7_afi_4: ps7-afi@0xFD3A0000 {
			compatible = "xlnx,ps7-afi-1.00.a";
			reg = < 0x00 0xfd3a0000 0x1000 >;
		};

		ps7_afi_5: ps7-afi@0xFD3B0000 {
			compatible = "xlnx,ps7-afi-1.00.a";
			reg = < 0x00 0xfd3b0000 0x1000 >;
		};

		gdma0_mr: gdma0mr {
			#address-cells = < 0x02 >;
			#size-cells = < 0x01 >;
			compatible = "simple-bus";
			ranges;
		};

		gdma0_mattr: gdma0mattr {
			compatible = "qemu:memory-transaction-attr";
			secure = < 0x00 >;
			requester-id = < 0x14e8 >;
			phandle = < 0x36 >;
		};

		gdma0: gdma0@0xFD500000 {
			compatible = "xlnx,zdma";
			reg = < 0x00 0xfd500000 0x1000 >;
			bus-width = < 0x80 >;
			interrupts = < 0x7c >;
			#stream-id-cells = < 0x01 >;
			dma = < 0x2a >;
			memattr = < 0x36 >;
		};

		gdma1_mr: gdma1mr {
			#address-cells = < 0x02 >;
			#size-cells = < 0x01 >;
			compatible = "simple-bus";
			ranges;
		};

		gdma1_mattr: gdma1mattr {
			compatible = "qemu:memory-transaction-attr";
			secure = < 0x00 >;
			requester-id = < 0x14e9 >;
			phandle = < 0x37 >;
		};

		gdma1: gdma1@0xFD510000 {
			compatible = "xlnx,zdma";
			reg = < 0x00 0xfd510000 0x1000 >;
			bus-width = < 0x80 >;
			interrupts = < 0x7d >;
			#stream-id-cells = < 0x01 >;
			dma = < 0x2a >;
			memattr = < 0x37 >;
		};

		gdma2_mr: gdma2mr {
			#address-cells = < 0x02 >;
			#size-cells = < 0x01 >;
			compatible = "simple-bus";
			ranges;
		};

		gdma2_mattr: gdma2mattr {
			compatible = "qemu:memory-transaction-attr";
			secure = < 0x00 >;
			requester-id = < 0x14ea >;
			phandle = < 0x38 >;
		};

		gdma2: gdma2@0xFD520000 {
			compatible = "xlnx,zdma";
			reg = < 0x00 0xfd520000 0x1000 >;
			bus-width = < 0x80 >;
			interrupts = < 0x7e >;
			#stream-id-cells = < 0x01 >;
			dma = < 0x2a >;
			memattr = < 0x38 >;
		};

		gdma3_mr: gdma3mr {
			#address-cells = < 0x02 >;
			#size-cells = < 0x01 >;
			compatible = "simple-bus";
			ranges;
		};

		gdma3_mattr: gdma3mattr {
			compatible = "qemu:memory-transaction-attr";
			secure = < 0x00 >;
			requester-id = < 0x14eb >;
			phandle = < 0x39 >;
		};

		gdma3: gdma3@0xFD530000 {
			compatible = "xlnx,zdma";
			reg = < 0x00 0xfd530000 0x1000 >;
			bus-width = < 0x80 >;
			interrupts = < 0x7f >;
			#stream-id-cells = < 0x01 >;
			dma = < 0x2a >;
			memattr = < 0x39 >;
		};

		gdma4_mr: gdma4mr {
			#address-cells = < 0x02 >;
			#size-cells = < 0x01 >;
			compatible = "simple-bus";
			ranges;
		};

		gdma4_mattr: gdma4mattr {
			compatible = "qemu:memory-transaction-attr";
			secure = < 0x00 >;
			requester-id = < 0x14ec >;
			phandle = < 0x3a >;
		};

		gdma4: gdma4@0xFD540000 {
			compatible = "xlnx,zdma";
			reg = < 0x00 0xfd540000 0x1000 >;
			bus-width = < 0x80 >;
			interrupts = < 0x80 >;
			#stream-id-cells = < 0x01 >;
			dma = < 0x2a >;
			memattr = < 0x3a >;
		};

		gdma5_mr: gdma5mr {
			#address-cells = < 0x02 >;
			#size-cells = < 0x01 >;
			compatible = "simple-bus";
			ranges;
		};

		gdma5_mattr: gdma5mattr {
			compatible = "qemu:memory-transaction-attr";
			secure = < 0x00 >;
			requester-id = < 0x14ed >;
			phandle = < 0x3b >;
		};

		gdma5: gdma5@0xFD550000 {
			compatible = "xlnx,zdma";
			reg = < 0x00 0xfd550000 0x1000 >;
			bus-width = < 0x80 >;
			interrupts = < 0x81 >;
			#stream-id-cells = < 0x01 >;
			dma = < 0x2a >;
			memattr = < 0x3b >;
		};

		gdma6_mr: gdma6mr {
			#address-cells = < 0x02 >;
			#size-cells = < 0x01 >;
			compatible = "simple-bus";
			ranges;
		};

		gdma6_mattr: gdma6mattr {
			compatible = "qemu:memory-transaction-attr";
			secure = < 0x00 >;
			requester-id = < 0x14ee >;
			phandle = < 0x3c >;
		};

		gdma6: gdma6@0xFD560000 {
			compatible = "xlnx,zdma";
			reg = < 0x00 0xfd560000 0x1000 >;
			bus-width = < 0x80 >;
			interrupts = < 0x82 >;
			#stream-id-cells = < 0x01 >;
			dma = < 0x2a >;
			memattr = < 0x3c >;
		};

		gdma7_mr: gdma7mr {
			#address-cells = < 0x02 >;
			#size-cells = < 0x01 >;
			compatible = "simple-bus";
			ranges;
		};

		gdma7_mattr: gdma7mattr {
			compatible = "qemu:memory-transaction-attr";
			secure = < 0x00 >;
			requester-id = < 0x14ef >;
			phandle = < 0x3d >;
		};

		gdma7: gdma7@0xFD570000 {
			compatible = "xlnx,zdma";
			reg = < 0x00 0xfd570000 0x1000 >;
			bus-width = < 0x80 >;
			interrupts = < 0x83 >;
			#stream-id-cells = < 0x01 >;
			dma = < 0x2a >;
			memattr = < 0x3d >;
		};

		crf: crf@0xFD1A0000 {
			compatible = "xlnx,zynqmp_crf";
			reg = < 0x00 0xfd1a0000 0x110 >;
			gpio-controller;
			#gpio-cells = < 0x01 >;
			phandle = < 0x66 >;
		};

		xlnx_dpdma: axidpdma@0xFD4C0000 {
			compatible = "xlnx,axi-dpdma-1.0";
			reg = < 0x00 0xfd4c0000 0x1000 >;
			clocks = < 0x3e >;
			clock-names = "axi_clk";
			xlnx,axi-clock-freq = < 0xbebc200 >;
			interrupts = < 0x7a >;
			dma = < 0x24 >;
			dma-channels = < 0x06 >;
			#dma-cells = < 0x01 >;
			phandle = < 0x40 >;

			dma-video0channel@fe4c0000 {
				compatible = "xlnx,video0";
			};

			dma-video1channel@fe4c0000 {
				compatible = "xlnx,video1";
			};

			dma-video2channel@fe4c0000 {
				compatible = "xlnx,video2";
			};

			dma-graphicschannel@fe4c0000 {
				compatible = "xlnx,graphics";
			};

			dma-audio0channel@fe4c0000 {
				compatible = "xlnx,audio0";
			};

			dma-audio1channel@fe4c0000 {
				compatible = "xlnx,audio1";
			};
		};

		dp_aclk: clock0 {
			compatible = "fixed-clock";
			#clock-cells = < 0x00 >;
			clock-frequency = < 0x2faf080 >;
			clock-accuracy = < 0x64 >;
			phandle = < 0x3f >;
		};

		dummy_clk: clock1 {
			compatible = "dummy-clk";
			#clock-cells = < 0x00 >;
			clock-frequency = < 0x2faf080 >;
			phandle = < 0x3e >;
		};

		xlnx_dp_sub: dp_sub@fd4aa000 {
			compatible = "xlnx,v-dp-sub-1.6";
			reg = < 0x00 0xfd4aa000 0x4000 >;
			xlnx,output-fmt = "rgb";
			phandle = < 0x41 >;
		};

		xlnx_dp: dp@0xFD4A0000 {
			compatible = "xlnx,v-dp-4.1";
			reg = < 0x00 0xfd4a0000 0x1000 >;
			interrupts = < 0x77 >;
			clock-names = "aclk";
			clocks = < 0x3f >;
			dpdma = < 0x40 >;
			xlnx,dp-version = "v1.2";
			xlnx,max-lanes = < 0x02 >;
			xlnx,max-link-rate = < 0x278d0 >;
			xlnx,max-bpc = < 0x10 >;
			xlnx,max-pclock = < 0x7530 >;
			xlnx,enable-ycrcb;
			xlnx,colormetry = "rgb";
			xlnx,bpc = < 0x08 >;
			xlnx,dp-sub = < 0x41 >;
			phandle = < 0x42 >;
		};

		xilinx_drm {
			compatible = "xlnx,drm";
			xlnx,encoder-slave = < 0x42 >;
			clocks = < 0x3e 0x00 >;
			xlnx,connector-type = "DisplayPort";
			xlnx,dp-sub = < 0x41 >;

			planes {
				xlnx,pixel-format = "rgb565";

				plane0 {
					dmas = < 0x40 0x03 >;
					dma-names = "dma";
				};

				plane1 {
					dmas = < 0x40 0x00 >;
					dma-names = "dma";
				};
			};
		};

		ddrphy_0: ddr-phy@0xFD080000 {
			compatible = "xlnx,zynqmp-ddr-phy";
			reg = < 0x00 0xfd080000 0x2000 >;
		};

		ddrc_0: memory-controller@0xFD070000 {
			compatible = "xlnx,zynqmp-ddrc";
			reg = < 0x00 0xfd070000 0x1000 >;
		};

		swdt@0xFF150000 {
			compatible = "xlnx,swdt";
			reg = < 0x00 0xff150000 0x10 >;
			pclk = < 0xf4240 >;
		};

		wdt@0xFD4D0000 {
			compatible = "xlnx,swdt";
			reg = < 0x00 0xfd4d0000 0x10 >;
			pclk = < 0xf4240 >;
		};

		csu_wdt@0xFFCB0000 {
			compatible = "xlnx,swdt";
			reg = < 0x00 0xffcb0000 0x10 >;
			pclk = < 0xf4240 >;
		};

		iou_slcr_0: zynqmp_iou_slcr@0xFF180000 {
			compatible = "xilinx,zynqmp-iou-slcr";
			reg = < 0x00 0xff180000 0x1000 >;
			gpio-controller;
			#gpio-cells = < 0x02 >;
			mio-bank0-1.8v = < 0x01 >;
			mio-bank1-1.8v = < 0x01 >;
			mio-bank2-1.8v = < 0x01 >;
			phandle = < 0x4c >;
		};

		ps7_can_0: ps7-can@0xFF060000 {
			clock-names = "ref_clk", "aper_clk";
			clocks = < 0x43 >, < 0x43 >;
			compatible = "xlnx,ps7-can-1.00.a";
			interrupts = < 0x17 >;
			reg = < 0x00 0xff060000 0x1000 >;
			xlnx,can-clk-freq-hz = < 0x5f5e100 >;
		};

		ps7_can_1: ps7-can@0xFF070000 {
			clock-names = "ref_clk", "aper_clk";
			clocks = < 0x43 >, < 0x43 >;
			compatible = "xlnx,ps7-can-1.00.a";
			interrupts = < 0x18 >;
			reg = < 0x00 0xff070000 0x1000 >;
			xlnx,can-clk-freq-hz = < 0x5f5e100 >;
		};

		serdes_0: serdes@0xFD400000 {
			compatible = "xlnx,zynqmp-serdes";
			reg = < 0x00 0xfd400000 0x20000 >;
		};

		gem0: gem0@0 {
			#address-cells = < 0x01 >;
			#size-cells = < 0x00 >;
			compatible = "cdns,gem";
			interrupts = < 0x39 0x39 >;
			dma = < 0x27 >;
			memattr = < 0x44 >;
			reg = < 0x00 0xff0b0000 0x1000 >;
			num-priority-queues = < 0x02 >;
			revision = < 0x40070106 >;
		};

		gem1: gem1@0 {
			#address-cells = < 0x01 >;
			#size-cells = < 0x00 >;
			compatible = "cdns,gem";
			interrupts = < 0x3b 0x3b >;
			dma = < 0x27 >;
			memattr = < 0x45 >;
			reg = < 0x00 0xff0c0000 0x1000 >;
			num-priority-queues = < 0x02 >;
			revision = < 0x40070106 >;
		};

		gem2: gem2@0 {
			#address-cells = < 0x01 >;
			#size-cells = < 0x00 >;
			compatible = "cdns,gem";
			interrupts = < 0x3d 0x3d >;
			dma = < 0x27 >;
			memattr = < 0x46 >;
			reg = < 0x00 0xff0d0000 0x1000 >;
			num-priority-queues = < 0x02 >;
			revision = < 0x40070106 >;
		};

		gem3: gem3@0 {
			#address-cells = < 0x01 >;
			#size-cells = < 0x00 >;
			compatible = "cdns,gem";
			interrupts = < 0x3f 0x3f >;
			dma = < 0x27 >;
			memattr = < 0x47 >;
			reg = < 0x00 0xff0e0000 0x1000 >;
			num-priority-queues = < 0x02 >;
			revision = < 0x40070106 >;
			mdio = < 0x48 >;
		};

		sata: ahci@0xFD0C0000 {
			compatible = "generic-ahci", "sysbus-ahci";
			reg = < 0x00 0xfd0c0000 0x2000 >;
			interrupts = < 0x85 >;
			num-ports = < 0x02 >;
			dma = < 0x24 >;
		};

		lpd_gpv@0xFE100000 {
			compatible = "xlnx,lpd-gpv";
			reg = < 0x00 0xfe100000 0xc8130 >;
		};

		usb3_0: usb3@0xFE200000 {
			compatible = "qemu,irq-test-component";
			reg = < 0x00 0xfe200000 0x4000 >;
			interrupts = < 0x4b >;
			gpios = < 0x15 0x07 0x00 0x16 0x07 >;
			gpio-names = "wake", "pwr_cntrl";
		};

		usb3_1: usb3@0xFE300000 {
			compatible = "qemu,irq-test-component";
			reg = < 0x00 0xfe300000 0x4000 >;
			interrupts = < 0x4c >;
			gpios = < 0x15 0x08 0x00 0x16 0x08 >;
			gpio-names = "wake", "pwr_cntrl";
		};

		nand: arasan_nfc@0xFF100000 {
			compatible = "arasan,nfc";
			reg = < 0x00 0xff100000 0x1000 >;
			interrupts = < 0x0e >;
			dma = < 0x24 >;
			has-mdma = < 0x01 >;

			nand {
				#address-cells = < 0x01 >;
				#size-cells = < 0x01 >;

				partition@0 {
					label = "all";
					reg = < 0x00 0x100000 >;
				};
			};
		};

		psu_gpio: psu_gpio@0xFF0A0000 {
			#gpio-cells = < 0x01 >;
			compatible = "xlnx,zynqmp-gpio";
			gpio-controller;
			interrupts = < 0x10 >;
			reg = < 0x00 0xff0a0000 0x1000 >;
		};

		qspi_dma_0: csu_dma@0xFF0F0800 {
			compatible = "zynqmp,csu-dma";
			interrupts = < 0x0f >;
			#stream-id-cells = < 0x01 >;
			reg = < 0x00 0xff0f0800 0x800 >;
			dma = < 0x27 >;
			memattr = < 0x49 >;
			is-dst = < 0x01 >;
			phandle = < 0x4a >;
		};

		ps7_qspi_0: ps7-qspi@0xFF0F0000 {
			#address-cells = < 0x01 >;
			#size-cells = < 0x00 >;
			#bus-cells = < 0x01 >;
			clock-names = "ref_clk", "pclk";
			compatible = "xlnx,usmp-gqspi", "cdns,spi-r1p6";
			stream-connected-dma = < 0x4a >;
			clocks = < 0x43 >, < 0x43 >;
			dma = < 0x24 >;
			interrupts = < 0x0f >;
			num-ss-bits = < 0x02 >;
			reg = < 0x00 0xff0f0000 0x1000 0x00 0xc0000000 0x8000000 >;
			speed-hz = < 0x989680 >;
			xlnx,fb-clk = < 0x01 >;
			xlnx,qspi-clk-freq-hz = < 0xbebc200 >;
			xlnx,qspi-mode = < 0x02 >;

			qspi_flash_lcs_lb: qspi_flash_lcs_lb@0 {
				#address-cells = < 0x01 >;
				#size-cells = < 0x01 >;
				#bus-cells = < 0x01 >;
				compatible = "n25q512a11", "st,m25p80";
				spi-max-frequency = < 0x2faf080 >;
				reg = < 0x00 0x00 >;

				qspi_flash_lcs_lb@0x00000000 {
					label = "qspi_flash_lcs_lb";
					reg = < 0x00 0x2000000 >;
				};
			};

			qspi_flash_ucs_ub: qspi_flash_ucs_ub@0 {
				#address-cells = < 0x01 >;
				#size-cells = < 0x01 >;
				#bus-cells = < 0x01 >;
				compatible = "n25q512a11", "st,m25p80";
				spi-max-frequency = < 0x2faf080 >;
				reg = < 0x03 0x01 >;

				qspi_flash_ucs_ub@0x00000000 {
					label = "qspi_flash_ucs_ub";
					reg = < 0x00 0x2000000 >;
				};
			};
		};

		sd_clk: sd_clk {
			#clock-cells = < 0x00 >;
			clock-frequency = < 0x17d7840 >;
			compatible = "fixed-clock";
			phandle = < 0x4b >;
		};

		ps7_sd_0: ps7-sdio@0xFF160000 {
			clock-names = "ref_clk", "aper_clk";
			clock-frequency = < 0x17d7840 >;
			compatible = "xilinx,zynqmp-sdhci", "generic-sdhci";
			clocks = < 0x4b >, < 0x4b >;
			drive-index = < 0x00 >;
			interrupts = < 0x30 >;
			reg = < 0x00 0xff160000 0x1000 >;
			dma = < 0x24 >;
			gpios = < 0x4c 0x00 0x00 >;
			gpio-names = "SLOTTYPE";
			is-mmc = < 0x00 >;
			xlnx,has-cd = < 0x01 >;
			xlnx,has-power = < 0x00 >;
			xlnx,has-wp = < 0x01 >;
			xlnx,sdio-clk-freq-hz = < 0x2faf080 >;
		};

		ps7_sd_1: ps7-sdio@0xFF170000 {
			clock-names = "ref_clk", "aper_clk";
			compatible = "xilinx,zynqmp-sdhci", "generic-sdhci";
			clocks = < 0x43 >, < 0x43 >;
			drive-index = < 0x01 >;
			interrupts = < 0x31 >;
			reg = < 0x00 0xff170000 0x1000 >;
			dma = < 0x24 >;
			gpios = < 0x4c 0x01 0x00 >;
			gpio-names = "SLOTTYPE";
			is-mmc = < 0x01 >;
			xlnx,has-cd = < 0x01 >;
			xlnx,has-power = < 0x00 >;
			xlnx,has-wp = < 0x01 >;
			xlnx,sdio-clk-freq-hz = < 0x2faf080 >;
		};

		ps7_spi_0: ps7-spi@0xFF040000 {
			#address-cells = < 0x01 >;
			#size-cells = < 0x00 >;
			clock-names = "ref_clk", "pclk";
			clocks = < 0x43 >, < 0x43 >;
			compatible = "cdns,spi-r1p6";
			interrupts = < 0x13 >;
			num-ss-bits = < 0x04 >;
			reg = < 0x00 0xff040000 0x1000 >;

			spi0_flash0: spi0_flash0@0 {
				#address-cells = < 0x01 >;
				#size-cells = < 0x01 >;
				#bus-cells = < 0x01 >;
				compatible = "sst25wf080", "st,m25p80";
				spi-max-frequency = < 0x2faf080 >;
				reg = < 0x00 0x00 >;

				spi0_flash0@0x00000000 {
					label = "spi0_flash0";
					reg = < 0x00 0x100000 >;
				};
			};

			spi0_flash1: spi0_flash1@0 {
				#address-cells = < 0x01 >;
				#size-cells = < 0x01 >;
				#bus-cells = < 0x01 >;
				compatible = "sst25wf080", "st,m25p80";
				spi-max-frequency = < 0x2faf080 >;
				reg = < 0x01 0x00 >;

				spi0_flash1@0x00000000 {
					label = "spi0_flash1";
					reg = < 0x00 0x100000 >;
				};
			};

			spi0_flash2: spi0_flash2@0 {
				#address-cells = < 0x01 >;
				#size-cells = < 0x01 >;
				#bus-cells = < 0x01 >;
				compatible = "sst25wf080", "st,m25p80";
				spi-max-frequency = < 0x2faf080 >;
				reg = < 0x02 0x00 >;

				spi0_flash2@0x00000000 {
					label = "spi0_flash2";
					reg = < 0x00 0x100000 >;
				};
			};

			spi0_flash3: spi0_flash3@0 {
				#address-cells = < 0x01 >;
				#size-cells = < 0x01 >;
				#bus-cells = < 0x01 >;
				compatible = "sst25wf080", "st,m25p80";
				spi-max-frequency = < 0x2faf080 >;
				reg = < 0x03 0x00 >;

				spi0_flash3@0x00000000 {
					label = "spi0_flash3";
					reg = < 0x00 0x100000 >;
				};
			};
		};

		ps7_spi_1: ps7-spi@0xFF050000 {
			#address-cells = < 0x01 >;
			#size-cells = < 0x00 >;
			clock-names = "ref_clk", "pclk";
			clocks = < 0x43 >, < 0x43 >;
			compatible = "cdns,spi-r1p6";
			interrupts = < 0x14 >;
			num-ss-bits = < 0x04 >;
			reg = < 0x00 0xff050000 0x1000 >;

			spi1_flash0: spi1_flash0@0 {
				#address-cells = < 0x01 >;
				#size-cells = < 0x01 >;
				#bus-cells = < 0x01 >;
				compatible = "sst25wf080", "st,m25p80";
				spi-max-frequency = < 0x2faf080 >;
				reg = < 0x00 0x00 >;

				spi1_flash0@0x00000000 {
					label = "spi1_flash0";
					reg = < 0x00 0x100000 >;
				};
			};

			spi1_flash1: spi1_flash1@0 {
				#address-cells = < 0x01 >;
				#size-cells = < 0x01 >;
				#bus-cells = < 0x01 >;
				compatible = "sst25wf080", "st,m25p80";
				spi-max-frequency = < 0x2faf080 >;
				reg = < 0x01 0x00 >;

				spi1_flash1@0x00000000 {
					label = "spi1_flash1";
					reg = < 0x00 0x100000 >;
				};
			};

			spi1_flash2: spi1_flash2@0 {
				#address-cells = < 0x01 >;
				#size-cells = < 0x01 >;
				#bus-cells = < 0x01 >;
				compatible = "sst25wf080", "st,m25p80";
				spi-max-frequency = < 0x2faf080 >;
				reg = < 0x02 0x00 >;

				spi1_flash2@0x00000000 {
					label = "spi1_flash2";
					reg = < 0x00 0x100000 >;
				};
			};

			spi1_flash3: spi1_flash3@0 {
				#address-cells = < 0x01 >;
				#size-cells = < 0x01 >;
				#bus-cells = < 0x01 >;
				compatible = "sst25wf080", "st,m25p80";
				spi-max-frequency = < 0x2faf080 >;
				reg = < 0x03 0x00 >;

				spi1_flash3@0x00000000 {
					label = "spi1_flash3";
					reg = < 0x00 0x100000 >;
				};
			};
		};

		ps7_ttc_0: ps7-ttc@0xFF110000 {
			clocks = < 0x43 >;
			compatible = "xlnx,ps7-ttc-1.00.a";
			interrupts = < 0x24 0x25 0x26 >;
			reg = < 0x00 0xff110000 0x1000 >;
			width = < 0x20 >;
		};

		ps7_ttc_1: ps7-ttc@0xFF120000 {
			clocks = < 0x43 >;
			compatible = "xlnx,ps7-ttc-1.00.a";
			interrupts = < 0x27 0x28 0x29 >;
			reg = < 0x00 0xff120000 0x1000 >;
			width = < 0x20 >;
		};

		ps7_ttc_2: ps7-ttc@0xFF130000 {
			clocks = < 0x43 >;
			compatible = "xlnx,ps7-ttc-1.00.a";
			interrupts = < 0x2a 0x2b 0x2c >;
			reg = < 0x00 0xff130000 0x1000 >;
			width = < 0x20 >;
		};

		ps7_ttc_3: ps7-ttc@0xFF140000 {
			clocks = < 0x43 >;
			compatible = "xlnx,ps7-ttc-1.00.a";
			interrupts = < 0x2d 0x2e 0x2f >;
			reg = < 0x00 0xff140000 0x1000 >;
			width = < 0x20 >;
		};

		uart_clk: uart_clk {
			#clock-cells = < 0x00 >;
			clock-frequency = < 0x17d7840 >;
			compatible = "fixed-clock";
			phandle = < 0x4d >;
		};

		ps7_uart_0: serial@0xFF000000 {
			compatible = "xlnx,ps7-uart-1.00.a", "xlnx,xuartps";
			current-speed = < 0x1c200 >;
			interrupts = < 0x15 >;
			port-number = < 0x01 >;
			reg = < 0x00 0xff000000 0x1000 >;
			xlnx,has-modem = < 0x00 >;
			xlnx,uart-clk-freq-hz = < 0x2faf080 >;
			clock-names = "uart_clk", "pclk";
			clocks = < 0x4d 0x4d >;
			ttrig-polarity = < 0x01 >;
		};

		ps7_uart_1: serial@0xFF010000 {
			compatible = "xlnx,ps7-uart-1.00.a", "xlnx,xuartps";
			current-speed = < 0x1c200 >;
			interrupts = < 0x16 >;
			port-number = < 0x00 >;
			reg = < 0x00 0xff010000 0x1000 >;
			xlnx,has-modem = < 0x00 >;
			xlnx,uart-clk-freq-hz = < 0x2faf080 >;
			clock-names = "uart_clk", "pclk";
			clocks = < 0x4d 0x4d >;
			ttrig-polarity = < 0x01 >;
			status = "disabled";
		};

		ocm_ctrl0: ocm_ctrl@0xFF960000 {
			compatible = "xlnx,zynqmp-ocmc";
			memsize = < 0x40000 >;
			reg = < 0x00 0xff960000 0x1000 >;
		};

		ocm_mem_ctrl_0: ocm_mem_ctrl_0@0 {
			compatible = "qemu,memory-controller";
			mr = < 0x4e >;
			gpios = < 0x16 0x10 0x16 0x0c >;
			gpio-names = "hlt_cntrl", "pwr_cntrl";
		};

		ocm_mem_ctrl_1: ocm_mem_ctrl_1@1 {
			compatible = "qemu,memory-controller";
			mr = < 0x4f >;
			gpios = < 0x16 0x11 0x16 0x0d >;
			gpio-names = "hlt_cntrl", "pwr_cntrl";
		};

		ocm_mem_ctrl_2: ocm_mem_ctrl_2@2 {
			compatible = "qemu,memory-controller";
			mr = < 0x50 >;
			gpios = < 0x16 0x12 0x16 0x0e >;
			gpio-names = "hlt_cntrl", "pwr_cntrl";
		};

		ocm_mem_ctrl_3: ocm_mem_ctrl_3@3 {
			compatible = "qemu,memory-controller";
			mr = < 0x51 >;
			gpios = < 0x16 0x13 0x16 0x0f >;
			gpio-names = "hlt_cntrl", "pwr_cntrl";
		};

		adma0_mr: adma0mr {
			#address-cells = < 0x02 >;
			#size-cells = < 0x01 >;
			compatible = "simple-bus";
			ranges;
		};

		adma0_mattr: adma0mattr {
			compatible = "qemu:memory-transaction-attr";
			secure = < 0x00 >;
			requester-id = < 0x868 >;
			phandle = < 0x52 >;
		};

		adma0: adma0@0xFFA80000 {
			compatible = "xlnx,zdma";
			reg = < 0x00 0xffa80000 0x1000 >;
			bus-width = < 0x40 >;
			interrupts = < 0x4d >;
			#stream-id-cells = < 0x01 >;
			dma = < 0x27 >;
			memattr = < 0x52 >;
		};

		adma1_mr: adma1mr {
			#address-cells = < 0x02 >;
			#size-cells = < 0x01 >;
			compatible = "simple-bus";
			ranges;
		};

		adma1_mattr: adma1mattr {
			compatible = "qemu:memory-transaction-attr";
			secure = < 0x00 >;
			requester-id = < 0x869 >;
			phandle = < 0x53 >;
		};

		adma1: adma1@0xFFA90000 {
			compatible = "xlnx,zdma";
			reg = < 0x00 0xffa90000 0x1000 >;
			bus-width = < 0x40 >;
			interrupts = < 0x4e >;
			#stream-id-cells = < 0x01 >;
			dma = < 0x27 >;
			memattr = < 0x53 >;
		};

		adma2_mr: adma2mr {
			#address-cells = < 0x02 >;
			#size-cells = < 0x01 >;
			compatible = "simple-bus";
			ranges;
		};

		adma2_mattr: adma2mattr {
			compatible = "qemu:memory-transaction-attr";
			secure = < 0x00 >;
			requester-id = < 0x86a >;
			phandle = < 0x54 >;
		};

		adma2: adma2@0xFFAA0000 {
			compatible = "xlnx,zdma";
			reg = < 0x00 0xffaa0000 0x1000 >;
			bus-width = < 0x40 >;
			interrupts = < 0x4f >;
			#stream-id-cells = < 0x01 >;
			dma = < 0x27 >;
			memattr = < 0x54 >;
		};

		adma3_mr: adma3mr {
			#address-cells = < 0x02 >;
			#size-cells = < 0x01 >;
			compatible = "simple-bus";
			ranges;
		};

		adma3_mattr: adma3mattr {
			compatible = "qemu:memory-transaction-attr";
			secure = < 0x00 >;
			requester-id = < 0x86b >;
			phandle = < 0x55 >;
		};

		adma3: adma3@0xFFAB0000 {
			compatible = "xlnx,zdma";
			reg = < 0x00 0xffab0000 0x1000 >;
			bus-width = < 0x40 >;
			interrupts = < 0x50 >;
			#stream-id-cells = < 0x01 >;
			dma = < 0x27 >;
			memattr = < 0x55 >;
		};

		adma4_mr: adma4mr {
			#address-cells = < 0x02 >;
			#size-cells = < 0x01 >;
			compatible = "simple-bus";
			ranges;
		};

		adma4_mattr: adma4mattr {
			compatible = "qemu:memory-transaction-attr";
			secure = < 0x00 >;
			requester-id = < 0x86c >;
			phandle = < 0x56 >;
		};

		adma4: adma4@0xFFAC0000 {
			compatible = "xlnx,zdma";
			reg = < 0x00 0xffac0000 0x1000 >;
			bus-width = < 0x40 >;
			interrupts = < 0x51 >;
			#stream-id-cells = < 0x01 >;
			dma = < 0x27 >;
			memattr = < 0x56 >;
		};

		adma5_mr: adma5mr {
			#address-cells = < 0x02 >;
			#size-cells = < 0x01 >;
			compatible = "simple-bus";
			ranges;
		};

		adma5_mattr: adma5mattr {
			compatible = "qemu:memory-transaction-attr";
			secure = < 0x00 >;
			requester-id = < 0x86d >;
			phandle = < 0x57 >;
		};

		adma5: adma5@0xFFAD0000 {
			compatible = "xlnx,zdma";
			reg = < 0x00 0xffad0000 0x1000 >;
			bus-width = < 0x40 >;
			interrupts = < 0x52 >;
			#stream-id-cells = < 0x01 >;
			dma = < 0x27 >;
			memattr = < 0x57 >;
		};

		adma6_mr: adma6mr {
			#address-cells = < 0x02 >;
			#size-cells = < 0x01 >;
			compatible = "simple-bus";
			ranges;
		};

		adma6_mattr: adma6mattr {
			compatible = "qemu:memory-transaction-attr";
			secure = < 0x00 >;
			requester-id = < 0x86e >;
			phandle = < 0x58 >;
		};

		adma6: adma6@0xFFAE0000 {
			compatible = "xlnx,zdma";
			reg = < 0x00 0xffae0000 0x1000 >;
			bus-width = < 0x40 >;
			interrupts = < 0x53 >;
			#stream-id-cells = < 0x01 >;
			dma = < 0x27 >;
			memattr = < 0x58 >;
		};

		adma7_mr: adma7mr {
			#address-cells = < 0x02 >;
			#size-cells = < 0x01 >;
			compatible = "simple-bus";
			ranges;
		};

		adma7_mattr: adma7mattr {
			compatible = "qemu:memory-transaction-attr";
			secure = < 0x00 >;
			requester-id = < 0x86f >;
			phandle = < 0x59 >;
		};

		adma7: adma7@0xFFAF0000 {
			compatible = "xlnx,zdma";
			reg = < 0x00 0xffaf0000 0x1000 >;
			bus-width = < 0x40 >;
			interrupts = < 0x54 >;
			#stream-id-cells = < 0x01 >;
			dma = < 0x27 >;
			memattr = < 0x59 >;
		};

		crl: crl@0xFF5E0000 {
			compatible = "xlnx,zynqmp-crl";
			reg = < 0x00 0xff5e0000 0x1000 >;
			gpio-controller;
			#gpio-cells = < 0x01 >;
			num-gpios = < 0x03 >;
			gpios = < 0x04 0x1a >;
			phandle = < 0x05 >;
		};

		gic_proxy: gic_proxy@0xff418000 {
			#interrupt-cells = < 0x03 >;
			reg = < 0x00 0xff418000 0x100 >;
			compatible = "xlnx,zynqmp-gicp";
			interrupt-controller;
			gpios = < 0x15 0x11 0x00 >;
			phandle = < 0x08 >;
		};

		zynqmp_anms: zynqmp_anms@0xFFA50000 {
			compatible = "xlnx,zynqmp_ams";
			reg = < 0x00 0xffa50000 0x68 >;
			gpio-controller;
			#gpio-cells = < 0x02 >;
		};

		zynqmp_sysmon_ps: zynqmp_sysmon_ps@0xFFA50800 {
			compatible = "xlnx,zynqmp_sysmon";
			reg = < 0x00 0xffa50800 0x200 >;
			gpio-controller;
			#gpio-cells = < 0x02 >;
		};

		zynqmp_sysmon_pl: zynqmp_sysmon_pl@0xFFA50C00 {
			compatible = "xlnx,zynqmp_sysmon";
			reg = < 0x00 0xffa50c00 0x200 >;
			gpio-controller;
			#gpio-cells = < 0x02 >;
		};

		zynqmp_rtc: zynqmp_rtc@0xFFA60000 {
			compatible = "xlnx-zynmp.rtc";
			reg = < 0x00 0xffa60000 0x100 >;
		};

		dummy_gpio: dummy_gpio@0 {
			gpio-controller;
			#gpio-cells = < 0x01 >;
			phandle = < 0x17 >;
		};

		cxtsgen: cxtsgen@0xFF250000 {
			compatible = "arm.generic-timer";
			reg = < 0x00 0xff260000 0x1000 >;
		};

		ps_reset@0 {
			compatible = "qemu,reset-device";
			gpios = < 0x05 0x02 0x04 0x03 >;
		};

		pcie_attrib: pcie_attrib@0xFD480000 {
			compatible = "xlnx.nwl-pcie-attrib";
			reg = < 0x00 0xfd480000 0x1000 >;
			interrupts = < 0x76 >;
		};

		pcie_main: pcie_main@0xFD0E0000 {
			compatible = "xlnx.nwl-pcie-main";
			reg-extended = < 0x23 0x00 0xfd0e0000 0x1000 0x5a 0x00 0xfd480000 0x00 0x1000 0x02 0x23 0x80 0x00 0x10000000 0x5b 0x00 0x00 0xffffffff 0xffffffff 0x00 >;
			interrupts = < 0x74 0x72 0x73 >;
			dma = < 0x5a >;
			memattr = < 0x5c >;
		};

		zynqmp_boot: zynqmp_boot@0 {
			compatible = "xlnx,zynqmp-boot";
			dma = < 0x23 >;
			gpios = < 0x16 0x00 >;
			gpios-names = "reset";
		};

		zynqmp_csu_dma_dst: csu_dma_dst@0xFFC80800 {
			compatible = "zynqmp,csu-dma";
			interrupts = < 0x56 >;
			reg = < 0x00 0xffc80800 0x800 >;
			dma = < 0x24 >;
			is-dst = < 0x01 >;
			memattr = < 0x5d >;
			phandle = < 0x84 >;
		};

		xlnx_csu_dma_src: csu_dma_src@0xFFC80000 {
			compatible = "zynqmp,csu-dma";
			interrupts = < 0x56 >;
			stream-connected-dma = < 0x5e >;
			reg = < 0x00 0xffc80000 0x800 >;
			dma = < 0x24 >;
			memattr = < 0x5d >;
		};

		rpu0_for_main_bus {
			compatible = "qemu:memory-region";
			alias = < 0x5f >;
			reg = < 0x00 0xffe00000 0x60000 >;
		};

		rpu1_for_main_bus {
			compatible = "qemu:memory-region";
			alias = < 0x60 >;
			reg = < 0x00 0xffe90000 0x50000 >;
		};

		i2c0: i2c0@0xFF020000 {
			#address-cells = < 0x01 >;
			#size-cells = < 0x00 >;
			clocks = < 0x43 >;
			compatible = "xlnx,ps7-i2c-1.00.a", "cdns,i2c-r1p10";
			interrupts = < 0x11 >;
			reg = < 0x00 0xff020000 0x1000 >;

			tca6416_u97: tca6416@20 {
				compatible = "ti,tca6416";
				reg = < 0x20 >;
			};

			tca6416_u61: tca6416@21 {
				compatible = "ti,tca6416";
				reg = < 0x21 >;
			};

			i2cswitch@75 {
				#address-cells = < 0x01 >;
				#size-cells = < 0x00 >;
				compatible = "nxp,pca9544";
				reg = < 0x74 >;
				chip-enable = < 0x01 >;

				i2c@0 {
					#address-cells = < 0x01 >;
					#size-cells = < 0x00 >;
					reg = < 0x00 >;

					ina226@40 {
						compatible = "i2c-dev-dummy";
						reg = < 0x40 >;
						shunt-resistor = < 0x1388 >;
					};

					ina226@41 {
						compatible = "i2c-dev-dummy";
						reg = < 0x41 >;
						shunt-resistor = < 0x1388 >;
					};

					ina226@42 {
						compatible = "i2c-dev-dummy";
						reg = < 0x42 >;
						shunt-resistor = < 0x1388 >;
					};

					ina226@43 {
						compatible = "i2c-dev-dummy";
						reg = < 0x43 >;
						shunt-resistor = < 0x1388 >;
					};

					ina226@44 {
						compatible = "i2c-dev-dummy";
						reg = < 0x44 >;
						shunt-resistor = < 0x1388 >;
					};

					ina226@45 {
						compatible = "i2c-dev-dummy";
						reg = < 0x45 >;
						shunt-resistor = < 0x1388 >;
					};

					ina226@46 {
						compatible = "i2c-dev-dummy";
						reg = < 0x46 >;
						shunt-resistor = < 0x1388 >;
					};

					ina226@47 {
						compatible = "i2c-dev-dummy";
						reg = < 0x47 >;
						shunt-resistor = < 0x1388 >;
					};

					ina226@4a {
						compatible = "i2c-dev-dummy";
						reg = < 0x4a >;
						shunt-resistor = < 0x1388 >;
					};

					ina226@4b {
						compatible = "i2c-dev-dummy";
						reg = < 0x4b >;
						shunt-resistor = < 0x1388 >;
					};
				};

				i2c@1 {
					#address-cells = < 0x01 >;
					#size-cells = < 0x00 >;
					reg = < 0x01 >;

					ina226@40 {
						compatible = "i2c-dev-dummy";
						reg = < 0x40 >;
						shunt-resistor = < 0x7d0 >;
					};

					ina226@41 {
						compatible = "i2c-dev-dummy";
						reg = < 0x41 >;
						shunt-resistor = < 0x1388 >;
					};

					ina226@42 {
						compatible = "i2c-dev-dummy";
						reg = < 0x42 >;
						shunt-resistor = < 0x1388 >;
					};

					ina226@43 {
						compatible = "i2c-dev-dummy";
						reg = < 0x43 >;
						shunt-resistor = < 0x1388 >;
					};

					ina226@44 {
						compatible = "i2c-dev-dummy";
						reg = < 0x44 >;
						shunt-resistor = < 0x1388 >;
					};

					ina226@45 {
						compatible = "i2c-dev-dummy";
						reg = < 0x45 >;
						shunt-resistor = < 0x1388 >;
					};

					ina226@46 {
						compatible = "i2c-dev-dummy";
						reg = < 0x46 >;
						shunt-resistor = < 0x1388 >;
					};

					ina226@47 {
						compatible = "i2c-dev-dummy";
						reg = < 0x47 >;
						shunt-resistor = < 0x1388 >;
					};
				};

				i2c@2 {
					#address-cells = < 0x01 >;
					#size-cells = < 0x00 >;
					reg = < 0x02 >;

					max15301@a {
						compatible = "i2c-dev-dummy";
						reg = < 0x0a >;
					};

					max15303@b {
						compatible = "i2c-dev-dummy";
						reg = < 0x0b >;
					};

					max15303@10 {
						compatible = "i2c-dev-dummy";
						reg = < 0x10 >;
					};

					max15301@13 {
						compatible = "i2c-dev-dummy";
						reg = < 0x13 >;
					};

					max15303@14 {
						compatible = "i2c-dev-dummy";
						reg = < 0x14 >;
					};

					max15303@15 {
						compatible = "i2c-dev-dummy";
						reg = < 0x15 >;
					};

					max15303@16 {
						compatible = "i2c-dev-dummy";
						reg = < 0x16 >;
					};

					max15303@17 {
						compatible = "i2c-dev-dummy";
						reg = < 0x17 >;
					};

					max15301@18 {
						compatible = "i2c-dev-dummy";
						reg = < 0x18 >;
					};

					max15303@1a {
						compatible = "i2c-dev-dummy";
						reg = < 0x1a >;
					};

					max15303@1d {
						compatible = "i2c-dev-dummy";
						reg = < 0x1d >;
					};

					max20751@72 {
						compatible = "i2c-dev-dummy";
						reg = < 0x72 >;
					};

					max20751@73 {
						compatible = "i2c-dev-dummy";
						reg = < 0x73 >;
					};
				};
			};
		};

		i2c1: i2c1@0xFF030000 {
			#address-cells = < 0x01 >;
			#size-cells = < 0x00 >;
			clocks = < 0x43 >;
			compatible = "xlnx,ps7-i2c-1.00.a", "cdns,i2c-r1p10";
			interrupts = < 0x12 >;
			reg = < 0x00 0xff030000 0x1000 >;

			i2cswitch@74 {
				#address-cells = < 0x01 >;
				#size-cells = < 0x00 >;
				compatible = "nxp,pca9548";
				reg = < 0x74 >;

				i2c@0 {
					#address-cells = < 0x01 >;
					#size-cells = < 0x00 >;
					reg = < 0x00 >;

					eeprom@54 {
						compatible = "at,24c08";
						reg = < 0x54 >;
					};

					eeprom@55 {
						compatible = "at,24c08";
						reg = < 0x55 >;
					};

					eeprom@56 {
						compatible = "at,24c08";
						reg = < 0x56 >;
					};

					eeprom@57 {
						compatible = "at,24c08";
						reg = < 0x57 >;
					};
				};

				i2c@1 {
					#address-cells = < 0x01 >;
					#size-cells = < 0x00 >;
					reg = < 0x01 >;

					si5341: clock-generator1@36 {
						compatible = "i2c-dev-dummy";
						reg = < 0x36 >;
					};
				};

				i2c@2 {
					#address-cells = < 0x01 >;
					#size-cells = < 0x00 >;
					reg = < 0x02 >;

					si570_1: clock-generator@5d {
						compatible = "silabs,si57x";
						reg = < 0x5d >;
						temperature-stability = < 0x32 >;
					};
				};

				i2c@3 {
					#address-cells = < 0x01 >;
					#size-cells = < 0x00 >;
					reg = < 0x03 >;

					si570_2: clock-generator@5e {
						compatible = "silabs,si57x";
						reg = < 0x5d >;
						temperature-stability = < 0x32 >;
					};
				};

				i2c@4 {
					#address-cells = < 0x01 >;
					#size-cells = < 0x00 >;
					reg = < 0x04 >;

					si5328: clock-generator4@69 {
						compatible = "i2c-dev-dummy";
						reg = < 0x69 >;
					};
				};
			};

			i2cswitch@75 {
				compatible = "nxp,pca9548";
				#address-cells = < 0x01 >;
				#size-cells = < 0x00 >;
				reg = < 0x74 >;
				chip-enable = < 0x01 >;

				i2c@0 {
					#address-cells = < 0x01 >;
					#size-cells = < 0x00 >;
					reg = < 0x00 >;
				};

				i2c@1 {
					#address-cells = < 0x01 >;
					#size-cells = < 0x00 >;
					reg = < 0x01 >;
				};

				i2c@2 {
					#address-cells = < 0x01 >;
					#size-cells = < 0x00 >;
					reg = < 0x02 >;
				};

				i2c@3 {
					#address-cells = < 0x01 >;
					#size-cells = < 0x00 >;
					reg = < 0x03 >;

					dev@19 {
						compatible = "xxx";
						reg = < 0x19 >;
					};

					dev@30 {
						compatible = "xxx";
						reg = < 0x30 >;
					};

					dev@35 {
						compatible = "xxx";
						reg = < 0x35 >;
					};

					dev@36 {
						compatible = "xxx";
						reg = < 0x36 >;
					};

					dev@37 {
						compatible = "i2c-dev-dummy";
						reg = < 0x37 >;
					};

					dev@51 {
						compatible = "sodimm-spd";
						reg = < 0x51 >;
					};
				};

				i2c@4 {
					#address-cells = < 0x01 >;
					#size-cells = < 0x00 >;
					reg = < 0x04 >;
				};

				i2c@5 {
					#address-cells = < 0x01 >;
					#size-cells = < 0x00 >;
					reg = < 0x05 >;
				};

				i2c@6 {
					#address-cells = < 0x01 >;
					#size-cells = < 0x00 >;
					reg = < 0x06 >;
				};

				i2c@7 {
					#address-cells = < 0x01 >;
					#size-cells = < 0x00 >;
					reg = < 0x07 >;
				};
			};
		};
	};

	lmb_pmu: lmb_pmu@0 {
		#address-cells = < 0x02 >;
		#size-cells = < 0x02 >;
		#priority-cells = < 0x01 >;
		compatible = "simple-bus";
		ranges;
		phandle = < 0x03 >;

		main_bus_for_pmu {
			compatible = "qemu:memory-region";
			alias = < 0x24 >;
			reg = < 0x00 0x00 0xffffffff 0xffffffff 0xffffffff >;
		};

		pmu_io_module: io-module@00 {
			#address-cells = < 0x02 >;
			#size-cells = < 0x01 >;
			#priority-cells = < 0x00 >;
			compatible = "xlnx,iomodule-1.02.a", "syscon", "simple-bus";
			container = < 0x03 >;
			priority = < 0xffffffff >;
			xlnx,freq = < 0x47868c0 >;
			xlnx,instance = "iomodule_1";
			xlnx,io-mask = < 0xfffe0000 >;
			xlnx,lmb-awidth = < 0x20 >;
			xlnx,lmb-dwidth = < 0x20 >;
			xlnx,mask = < 0xffffff80 >;
			xlnx,use-io-bus = < 0x01 >;

			pmu_io_intc: pmu_intc@0C {
				#interrupt-cells = < 0x02 >;
				compatible = "xlnx,io-intc-1.02.a", "xlnx,io_intc";
				interrupt-controller;
				interrupts-extended = < 0x61 0x00 >;
				reg = < 0x00 0xffd4000c 0x04 0x00 0xffd40030 0x10 0x00 0xffd40080 0x7c >;
				xlnx,intc-addr-width = < 0x20 >;
				xlnx,intc-base-vectors = < 0x00 >;
				xlnx,intc-has-fast = < 0x00 >;
				xlnx,intc-intr-size = < 0x10 >;
				xlnx,intc-level-edge = < 0x00 >;
				xlnx,intc-positive = < 0xffff >;
				xlnx,intc-use-ext-intr = < 0x01 >;
				phandle = < 0x13 >;
			};

			pmu_io_gpi1: pmu_gpi@20 {
				#gpio-cells = < 0x02 >;
				gpio-controller;
				compatible = "xlnx,io-gpi-1.02.a", "xlnx,io_gpi";
				interrupt-parent = < 0x13 >;
				interrupts = < 0x0b 0x00 >;
				reg = < 0x00 0xffd40020 0x04 >;
				xlnx,gpi-interrupt = < 0x01 >;
				xlnx,gpi-size = < 0x20 >;
				xlnx,use-gpi = < 0x01 >;
			};

			pmu_io_gpi2: pmu_gpi@24 {
				#gpio-cells = < 0x02 >;
				gpio-controller;
				compatible = "xlnx,io-gpi-1.02.a", "xlnx,io_gpi";
				interrupt-parent = < 0x13 >;
				interrupts = < 0x0c 0x00 >;
				reg = < 0x00 0xffd40024 0x04 >;
				xlnx,gpi-interrupt = < 0x01 >;
				xlnx,gpi-size = < 0x20 >;
				xlnx,use-gpi = < 0x01 >;
				gpios = < 0x16 0x1d >;
				phandle = < 0x15 >;
			};

			pmu_io_gpi3: pmu_gpi@28 {
				#gpio-cells = < 0x02 >;
				gpio-controller;
				compatible = "xlnx,io-gpi-1.02.a", "xlnx,io_gpi";
				interrupt-parent = < 0x13 >;
				interrupts = < 0x0d 0x00 >;
				reg = < 0x00 0xffd40028 0x04 >;
				xlnx,gpi-interrupt = < 0x01 >;
				xlnx,gpi-size = < 0x20 >;
				xlnx,use-gpi = < 0x01 >;
				gpios = < 0x16 0x1e >;
				phandle = < 0x0d >;
			};

			pmu_io_gpi4: pmu_gpi@2c {
				#gpio-cells = < 0x02 >;
				gpio-controller;
				compatible = "xlnx,io-gpi-1.02.a", "xlnx,io_gpi";
				interrupt-parent = < 0x13 >;
				interrupts = < 0x0e 0x00 >;
				reg = < 0x00 0xffd4002c 0x04 >;
				xlnx,gpi-interrupt = < 0x01 >;
				xlnx,gpi-size = < 0x20 >;
				xlnx,use-gpi = < 0x01 >;
			};

			pmu_io_gpo1: pmu_gpo@10 {
				#gpio-cells = < 0x02 >;
				gpio-controller;
				compatible = "xlnx,io-gpo-1.02.a", "xlnx,io_gpo";
				reg = < 0x00 0xffd40010 0x04 >;
				xlnx,gpo-init = < 0x00 >;
				xlnx,gpo-size = < 0x09 >;
				xlnx,use-gpo = < 0x01 >;
				phandle = < 0x62 >;
			};

			pmu_io_gpo2: pmu_gpo@14 {
				#gpio-cells = < 0x02 >;
				gpio-controller;
				compatible = "xlnx,io-gpo-1.02.a", "xlnx,io_gpo";
				reg = < 0x00 0xffd40014 0x04 >;
				xlnx,gpo-init = < 0x00 >;
				xlnx,gpo-size = < 0x20 >;
				xlnx,use-gpo = < 0x01 >;
			};

			pmu_io_gpo3: pmu_gpo@18 {
				#gpio-cells = < 0x02 >;
				gpio-controller;
				compatible = "xlnx,io-gpo-1.02.a", "xlnx,io_gpo";
				reg = < 0x00 0xffd40018 0x04 >;
				xlnx,gpo-init = < 0x00 >;
				xlnx,gpo-size = < 0x20 >;
				xlnx,use-gpo = < 0x01 >;
			};

			pmu_io_gpo4: pmu_gpo@1c {
				#gpio-cells = < 0x02 >;
				gpio-controller;
				compatible = "xlnx,io-gpo-1.02.a", "xlnx,io_gpo";
				reg = < 0x00 0xffd4001c 0x04 >;
				xlnx,gpo-init = < 0x00 >;
				xlnx,gpo-size = < 0x20 >;
				xlnx,use-gpo = < 0x01 >;
			};

			pmu_io_pit1: pmu_pit@40 {
				compatible = "xlnx,io-pit-1.02.a", "xlnx,io_pit";
				interrupt-parent = < 0x13 >;
				interrupts = < 0x03 0x00 >;
				reg = < 0x00 0xffd40040 0x0c >;
				xlnx,pit-interrupt = < 0x01 >;
				xlnx,pit-prescaler = < 0x09 >;
				xlnx,pit-readable = < 0x01 >;
				xlnx,pit-size = < 0x20 >;
				xlnx,use-pit = < 0x01 >;
				gpios = < 0x62 0x02 0x00 0x63 0x00 >;
				gpio-names = "ps_config", "ps_hit_in";
				gpio-controller;
				#gpio-cells = < 0x01 >;
			};

			pmu_io_pit2: pmu_pit@50 {
				compatible = "xlnx,io-pit-1.02.a", "xlnx,io_pit";
				interrupt-parent = < 0x13 >;
				interrupts = < 0x04 0x00 >;
				reg = < 0x00 0xffd40050 0x0c >;
				xlnx,pit-interrupt = < 0x01 >;
				xlnx,pit-prescaler = < 0x09 >;
				xlnx,pit-readable = < 0x01 >;
				xlnx,pit-size = < 0x20 >;
				xlnx,use-pit = < 0x01 >;
				gpio-controller;
				#gpio-cells = < 0x01 >;
				phandle = < 0x63 >;
			};

			pmu_io_pit3: pmu_pit@60 {
				compatible = "xlnx,io-pit-1.02.a", "xlnx,io_pit";
				interrupt-parent = < 0x13 >;
				interrupts = < 0x05 0x00 >;
				reg = < 0x00 0xffd40060 0x0c >;
				xlnx,pit-interrupt = < 0x01 >;
				xlnx,pit-prescaler = < 0x09 >;
				xlnx,pit-readable = < 0x01 >;
				xlnx,pit-size = < 0x20 >;
				xlnx,use-pit = < 0x01 >;
				gpios = < 0x62 0x06 0x00 0x64 0x00 >;
				gpio-names = "ps_config", "ps_hit_in";
				gpio-controller;
				#gpio-cells = < 0x01 >;
			};

			pmu_io_pit4: pmu_pit@70 {
				compatible = "xlnx,io-pit-1.02.a", "xlnx,io_pit";
				interrupt-parent = < 0x13 >;
				interrupts = < 0x06 0x00 >;
				reg = < 0x00 0xffd40070 0x0c >;
				xlnx,pit-interrupt = < 0x01 >;
				xlnx,pit-prescaler = < 0x09 >;
				xlnx,pit-readable = < 0x01 >;
				xlnx,pit-size = < 0x20 >;
				xlnx,use-pit = < 0x01 >;
				gpio-controller;
				#gpio-cells = < 0x01 >;
				phandle = < 0x64 >;
			};

			pmu_io_uart: pmu_uart@00 {
				compatible = "xlnx,io-uart-1.02.a", "xlnx,io_uart";
				interrupt-parent = < 0x13 >;
				interrupts = < 0x00 0x00 0x01 0x00 0x02 0x00 >;
				reg = < 0x00 0xffd40000 0x0c 0x00 0xffd4004c 0x04 >;
				xlnx,uart-baudrate = < 0x2580 >;
				xlnx,uart-data-bits = < 0x08 >;
				xlnx,uart-error-interrupt = < 0x01 >;
				xlnx,uart-odd-parity = < 0x00 >;
				xlnx,uart-prog-baudrate = < 0x00 >;
				xlnx,uart-rx-interrupt = < 0x01 >;
				xlnx,uart-tx-interrupt = < 0x01 >;
				xlnx,uart-use-parity = < 0x00 >;
				xlnx,use-uart-rx = < 0x00 >;
				xlnx,use-uart-tx = < 0x00 >;
			};
		};

		pmu_local: pmu_local@ffd60000 {
			#gpio-cells = < 0x01 >;
			compatible = "xlnx,pmu-local";
			reg = < 0x00 0xffd60000 0x00 0x1000 0x00 >;
			gpio-controller;
			num-gpios = < 0x07 >;
			phandle = < 0x16 >;
		};
	};

	cpus {
		#address-cells = < 0x01 >;
		#size-cells = < 0x00 >;

		cpu0: apu_cpu@0 {
			compatible = "cortex-a53-arm-cpu";
			d-cache-line-size = < 0x20 >;
			d-cache-size = < 0x8000 >;
			device_type = "cpu";
			i-cache-line-size = < 0x20 >;
			i-cache-size = < 0x8000 >;
			arm,midr = < 0x410fd034 >;
			arm,ctr = < 0x83338003 >;
			arm,clidr = < 0x9200003 >;
			arm,id_pfr0 = < 0x1231 >;
			arm,ccsidr0 = < 0x701fe019 >;
			arm,ccsidr1 = < 0x201fe019 >;
			arm,mp-affinity = < 0x00 >;
			enable-method = "psci";
			reg = < 0x00 >;
			core-count = < 0x04 >;
			arm,reset-hivecs = < 0x01 >;
			arm,rvbar = < 0xffff0000 >;
			#interrupt-cells = < 0x01 >;
			arm,reset-cbar = < 0xfd3fe000 >;
			mr = < 0x65 >;
			memory = < 0x65 >;
			gpios = < 0x66 0x00 0x67 0x00 0x16 0x80000001 0x16 0x8000001c 0x04 0x02 >;
			gpio-names = "rst_cntrl", "wfi", "pwr_cntrl", "pwr_cntrl", "rst_cntrl";
			gdb-id = "Cortex-A53 #0";
			memattr_s = < 0x68 >;
			memattr_ns = < 0x69 >;
			phandle = < 0x09 >;
		};

		cpu1: apu_cpu@1 {
			compatible = "cortex-a53-arm-cpu";
			d-cache-line-size = < 0x20 >;
			d-cache-size = < 0x8000 >;
			device_type = "cpu";
			i-cache-line-size = < 0x20 >;
			i-cache-size = < 0x8000 >;
			arm,midr = < 0x410fd034 >;
			arm,ctr = < 0x83338003 >;
			arm,clidr = < 0x9200003 >;
			arm,id_pfr0 = < 0x1231 >;
			arm,ccsidr0 = < 0x701fe019 >;
			arm,ccsidr1 = < 0x201fe019 >;
			arm,mp-affinity = < 0x01 >;
			enable-method = "psci";
			reg = < 0x01 >;
			core-count = < 0x04 >;
			arm,reset-hivecs = < 0x01 >;
			arm,rvbar = < 0xffff0000 >;
			#interrupt-cells = < 0x01 >;
			arm,reset-cbar = < 0xfd3fe000 >;
			mr = < 0x65 >;
			memory = < 0x65 >;
			gpios = < 0x66 0x01 0x67 0x01 0x16 0x80000002 0x16 0x8000001c 0x04 0x02 >;
			gpio-names = "rst_cntrl", "wfi", "pwr_cntrl", "pwr_cntrl", "rst_cntrl";
			gdb-id = "Cortex-A53 #1";
			memattr_s = < 0x6a >;
			memattr_ns = < 0x6b >;
			phandle = < 0x0a >;
		};

		cpu2: apu_cpu@2 {
			compatible = "cortex-a53-arm-cpu";
			d-cache-line-size = < 0x20 >;
			d-cache-size = < 0x8000 >;
			device_type = "cpu";
			i-cache-line-size = < 0x20 >;
			i-cache-size = < 0x8000 >;
			arm,midr = < 0x410fd034 >;
			arm,ctr = < 0x83338003 >;
			arm,clidr = < 0x9200003 >;
			arm,id_pfr0 = < 0x1231 >;
			arm,ccsidr0 = < 0x701fe019 >;
			arm,ccsidr1 = < 0x201fe019 >;
			arm,mp-affinity = < 0x02 >;
			enable-method = "psci";
			reg = < 0x02 >;
			core-count = < 0x04 >;
			arm,reset-hivecs = < 0x01 >;
			arm,rvbar = < 0xffff0000 >;
			#interrupt-cells = < 0x01 >;
			arm,reset-cbar = < 0xfd3fe000 >;
			mr = < 0x65 >;
			memory = < 0x65 >;
			gpios = < 0x66 0x02 0x67 0x02 0x16 0x80000003 0x16 0x8000001c 0x04 0x02 >;
			gpio-names = "rst_cntrl", "wfi", "pwr_cntrl", "pwr_cntrl", "rst_cntrl";
			gdb-id = "Cortex-A53 #2";
			memattr_s = < 0x6c >;
			memattr_ns = < 0x6d >;
			phandle = < 0x0b >;
		};

		cpu3: apu_cpu@3 {
			compatible = "cortex-a53-arm-cpu";
			d-cache-line-size = < 0x20 >;
			d-cache-size = < 0x8000 >;
			device_type = "cpu";
			i-cache-line-size = < 0x20 >;
			i-cache-size = < 0x8000 >;
			arm,midr = < 0x410fd034 >;
			arm,ctr = < 0x83338003 >;
			arm,clidr = < 0x9200003 >;
			arm,id_pfr0 = < 0x1231 >;
			arm,ccsidr0 = < 0x701fe019 >;
			arm,ccsidr1 = < 0x201fe019 >;
			arm,mp-affinity = < 0x03 >;
			enable-method = "psci";
			reg = < 0x03 >;
			core-count = < 0x04 >;
			arm,reset-hivecs = < 0x01 >;
			arm,rvbar = < 0xffff0000 >;
			#interrupt-cells = < 0x01 >;
			arm,reset-cbar = < 0xfd3fe000 >;
			mr = < 0x65 >;
			memory = < 0x65 >;
			gpios = < 0x66 0x03 0x67 0x03 0x16 0x80000004 0x16 0x8000001c 0x04 0x02 >;
			gpio-names = "rst_cntrl", "wfi", "pwr_cntrl", "pwr_cntrl", "rst_cntrl";
			gdb-id = "Cortex-A53 #3";
			memattr_s = < 0x6e >;
			memattr_ns = < 0x6f >;
			phandle = < 0x0c >;
		};

		rpu_cpu0: rpu_cpu@0 {
			compatible = "cortex-r5f-arm-cpu";
			d-cache-line-size = < 0x20 >;
			d-cache-size = < 0x8000 >;
			device_type = "cpu";
			i-cache-line-size = < 0x20 >;
			i-cache-size = < 0x8000 >;
			arm,midr = < 0x411fc153 >;
			arm,tcmtr = < 0x10001 >;
			arm,ctr = < 0x8003c003 >;
			arm,clidr = < 0x9200003 >;
			arm,ccsidr0 = < 0xf01fe019 >;
			arm,ccsidr1 = < 0xf01fe019 >;
			arm,mp-affinity = < 0x100 >;
			arm,id_pfr0 = < 0x131 >;
			arm,reset-hivecs = < 0x01 >;
			#interrupt-cells = < 0x01 >;
			reg = < 0x00 >;
			mr = < 0x70 >;
			memory = < 0x70 >;
			gpios = < 0x05 0x00 0x71 0x00 0x71 0x05 0x71 0x07 0x16 0x09 >;
			gpio-names = "reset", "ncpuhalt", "vinithi", "wfi", "pwr_cntrl";
			gdb-id = "Cortex-R5 #0";
			memattr_ns = < 0x72 >;
			phandle = < 0x7b >;
		};

		rpu_cpu1: rpu_cpu@1 {
			compatible = "cortex-r5f-arm-cpu";
			d-cache-line-size = < 0x20 >;
			d-cache-size = < 0x8000 >;
			device_type = "cpu";
			i-cache-line-size = < 0x20 >;
			i-cache-size = < 0x8000 >;
			arm,midr = < 0x411fc153 >;
			arm,tcmtr = < 0x10001 >;
			arm,ctr = < 0x8003c003 >;
			arm,clidr = < 0x9200003 >;
			arm,ccsidr0 = < 0xf01fe019 >;
			arm,ccsidr1 = < 0xf01fe019 >;
			arm,mp-affinity = < 0x101 >;
			arm,id_pfr0 = < 0x131 >;
			arm,reset-hivecs = < 0x01 >;
			#interrupt-cells = < 0x01 >;
			reg = < 0x01 >;
			mr = < 0x73 >;
			memory = < 0x73 >;
			gpios = < 0x05 0x01 0x71 0x02 0x71 0x01 0x71 0x06 0x71 0x08 0x16 0x09 >;
			gpio-names = "reset", "halt", "ncpuhalt", "vinithi", "wfi", "pwr_cntrl";
			gdb-id = "Cortex-R5 #1";
			memattr_ns = < 0x74 >;
			phandle = < 0x7c >;
		};
	};

	aliases {
		serial0 = "/amba@0/serial@0xFF000000";
		serial1 = "/amba@0/serial@0xFF010000";
		ethernet0 = "/amba@0/gem3@0";

		main_bus_for_apu {
			compatible = "qemu:memory-region";
			container = < 0x65 >;
			alias = < 0x2c >;
			priority = < 0xffffffff >;
		};

		main_bus_for_pl {
			compatible = "qemu:memory-region";
			container = < 0x23 >;
			alias = < 0x75 >;
			priority = < 0xffffffff >;
		};
	};

	amba_apu: amba_apu@0 {
		#address-cells = < 0x02 >;
		#size-cells = < 0x01 >;
		compatible = "xlnx,ps7-axi-interconnect-1.00.a", "simple-bus";
		ranges;
		phandle = < 0x65 >;

		timer {
			compatible = "arm,armv8-timer";
			interrupt-parent = < 0x06 >;
			interrupts = < 0x01 0x0d 0xff01 >, < 0x01 0x0e 0xff01 >, < 0x01 0x0b 0xff01 >, < 0x01 0x0a 0xff01 >;
			clock-frequency = < 0x5f5e100 >;
		};

		dummy: dymmy@0 {
			interrupt-controller;
			#interrupt-cells = < 0x01 >;
			phandle = < 0x7a >;
		};

		apu_intc_redirect_0: apu_intc_redirect0@0 {
			#interrupt-cells = < 0x01 >;
			compatible = "xlnx,zynqmp-intc-redirect";
			interrupt-controller;
			interrupts-extended = < 0x09 0x00 >, < 0x09 0x01 >, < 0x09 0x02 >, < 0x09 0x03 >;
			gpios = < 0x15 0x01 0x00 0x67 0x04 >;
			phandle = < 0x76 >;
		};

		apu_intc_redirect_1: apu_intc_redirect1@1 {
			#interrupt-cells = < 0x01 >;
			compatible = "xlnx,zynqmp-intc-redirect";
			interrupt-controller;
			interrupts-extended = < 0x0a 0x00 >, < 0x0a 0x01 >, < 0x0a 0x02 >, < 0x0a 0x03 >;
			gpios = < 0x15 0x02 0x00 0x67 0x05 >;
			phandle = < 0x77 >;
		};

		apu_intc_redirect_2: apu_intc_redirect2@2 {
			#interrupt-cells = < 0x01 >;
			compatible = "xlnx,zynqmp-intc-redirect";
			interrupt-controller;
			interrupts-extended = < 0x0b 0x00 >, < 0x0b 0x01 >, < 0x0b 0x02 >, < 0x0b 0x03 >;
			gpios = < 0x15 0x03 0x00 0x67 0x06 >;
			phandle = < 0x78 >;
		};

		apu_intc_redirect_3: apu_intc_redirect3@3 {
			#interrupt-cells = < 0x01 >;
			compatible = "xlnx,zynqmp-intc-redirect";
			interrupt-controller;
			interrupts-extended = < 0x0c 0x00 >, < 0x0c 0x01 >, < 0x0c 0x02 >, < 0x0c 0x03 >;
			gpios = < 0x15 0x04 0x00 0x67 0x07 >;
			phandle = < 0x79 >;
		};
	};

	amba_apu_gic: amba_apu_gic@0 {
		#address-cells = < 0x02 >;
		#priority-cells = < 0x01 >;
		#size-cells = < 0x01 >;
		compatible = "xlnx,ps7-axi-interconnect-1.00.a", "simple-bus";
		ranges;
		container = < 0x23 >;
		priority = < 0xffffffff >;

		gic: interrupt-controller@0xFD3FF000 {
			#address-cells = < 0x00 >;
			#size-cells = < 0x00 >;
			#interrupt-cells = < 0x03 >;
			#gpio-cells = < 0x00 >;
			compatible = "xlnx,zynqmp-scugic", "arm,gic";
			reg = < 0x00 0xf9010000 0x1000 0x00 0x00 0xf9020000 0x20000 0x00 0x00 0xf9040000 0x20000 0x00 0x00 0xf9060000 0x20000 0x00 >;
			interrupt-controller;
			gpios = < 0x16 0x1c 0x04 0x02 >;
			gpio-names = "pwr_cntrl", "rst_cntrl";
			num-irq = < 0xc0 >;
			interrupts-extended = < 0x76 0x00 >, < 0x77 0x00 >, < 0x78 0x00 >, < 0x79 0x00 >, < 0x7a 0x00 >, < 0x7a 0x00 >, < 0x7a 0x00 >, < 0x7a 0x00 >, < 0x76 0x02 >, < 0x77 0x02 >, < 0x78 0x02 >, < 0x79 0x02 >, < 0x7a 0x00 >, < 0x7a 0x00 >, < 0x7a 0x00 >, < 0x7a 0x00 >, < 0x76 0x01 >, < 0x77 0x01 >, < 0x78 0x01 >, < 0x79 0x01 >, < 0x7a 0x00 >, < 0x7a 0x00 >, < 0x7a 0x00 >, < 0x7a 0x00 >, < 0x76 0x03 >, < 0x77 0x03 >, < 0x78 0x03 >, < 0x79 0x03 >, < 0x7a 0x00 >, < 0x7a 0x00 >, < 0x7a 0x00 >, < 0x7a 0x00 >, < 0x06 0x01 0x09 0x104 >, < 0x06 0x01 0x09 0x204 >, < 0x06 0x01 0x09 0x404 >, < 0x06 0x01 0x09 0x804 >;
			num-cpu = < 0x04 >;
			revision = < 0x02 >;
			has-security-extensions = < 0x01 >;
			map-stride = < 0x10000 >;
			int-id = < 0x202143b >;
			phandle = < 0x06 >;
		};

		zynqmp-gic-cpu-alias@0xf9021000 {
			compatible = "qemu:memory-region";
			alias = < 0x06 0x01 >;
			reg = < 0x00 0xf9021000 0x1000 0x01 >;
		};

		zynqmp-gic-cpu-alias@0xf9022000 {
			compatible = "qemu:memory-region";
			alias = < 0x06 0x01 >;
			reg = < 0x00 0xf9022000 0x1000 0x01 >;
		};

		zynqmp-gic-cpu-alias@0xf9023000 {
			compatible = "qemu:memory-region";
			alias = < 0x06 0x01 >;
			reg = < 0x00 0xf9023000 0x1000 0x01 >;
		};

		zynqmp-gic-cpu-alias@0xf9024000 {
			compatible = "qemu:memory-region";
			alias = < 0x06 0x01 >;
			reg = < 0x00 0xf9024000 0x1000 0x01 >;
		};

		zynqmp-gic-cpu-alias@0xf9025000 {
			compatible = "qemu:memory-region";
			alias = < 0x06 0x01 >;
			reg = < 0x00 0xf9025000 0x1000 0x01 >;
		};

		zynqmp-gic-cpu-alias@0xf9026000 {
			compatible = "qemu:memory-region";
			alias = < 0x06 0x01 >;
			reg = < 0x00 0xf9026000 0x1000 0x01 >;
		};

		zynqmp-gic-cpu-alias@0xf9027000 {
			compatible = "qemu:memory-region";
			alias = < 0x06 0x01 >;
			reg = < 0x00 0xf9027000 0x1000 0x01 >;
		};

		zynqmp-gic-cpu-alias@0xf9028000 {
			compatible = "qemu:memory-region";
			alias = < 0x06 0x01 >;
			reg = < 0x00 0xf9028000 0x1000 0x01 >;
		};

		zynqmp-gic-cpu-alias@0xf9029000 {
			compatible = "qemu:memory-region";
			alias = < 0x06 0x01 >;
			reg = < 0x00 0xf9029000 0x1000 0x01 >;
		};

		zynqmp-gic-cpu-alias@0xf902a000 {
			compatible = "qemu:memory-region";
			alias = < 0x06 0x01 >;
			reg = < 0x00 0xf902a000 0x1000 0x01 >;
		};

		zynqmp-gic-cpu-alias@0xf902b000 {
			compatible = "qemu:memory-region";
			alias = < 0x06 0x01 >;
			reg = < 0x00 0xf902b000 0x1000 0x01 >;
		};

		zynqmp-gic-cpu-alias@0xf902c000 {
			compatible = "qemu:memory-region";
			alias = < 0x06 0x01 >;
			reg = < 0x00 0xf902c000 0x1000 0x01 >;
		};

		zynqmp-gic-cpu-alias@0xf902d000 {
			compatible = "qemu:memory-region";
			alias = < 0x06 0x01 >;
			reg = < 0x00 0xf902d000 0x1000 0x01 >;
		};

		zynqmp-gic-cpu-alias@0xf902e000 {
			compatible = "qemu:memory-region";
			alias = < 0x06 0x01 >;
			reg = < 0x00 0xf902e000 0x1000 0x01 >;
		};

		zynqmp-gic-cpu-alias@0xf902f000 {
			compatible = "qemu:memory-region";
			alias = < 0x06 0x01 >;
			reg = < 0x00 0xf902f000 0x1000 0x01 >;
		};

		zynqmp-gic-vcpu-alias@0xf9061000 {
			compatible = "qemu:memory-region";
			alias = < 0x06 0x03 >;
			reg = < 0x00 0xf9061000 0x1000 0x01 >;
		};

		zynqmp-gic-vcpu-alias@0xf9062000 {
			compatible = "qemu:memory-region";
			alias = < 0x06 0x03 >;
			reg = < 0x00 0xf9062000 0x1000 0x01 >;
		};

		zynqmp-gic-vcpu-alias@0xf9063000 {
			compatible = "qemu:memory-region";
			alias = < 0x06 0x03 >;
			reg = < 0x00 0xf9063000 0x1000 0x01 >;
		};

		zynqmp-gic-vcpu-alias@0xf9064000 {
			compatible = "qemu:memory-region";
			alias = < 0x06 0x03 >;
			reg = < 0x00 0xf9064000 0x1000 0x01 >;
		};

		zynqmp-gic-vcpu-alias@0xf9065000 {
			compatible = "qemu:memory-region";
			alias = < 0x06 0x03 >;
			reg = < 0x00 0xf9065000 0x1000 0x01 >;
		};

		zynqmp-gic-vcpu-alias@0xf9066000 {
			compatible = "qemu:memory-region";
			alias = < 0x06 0x03 >;
			reg = < 0x00 0xf9066000 0x1000 0x01 >;
		};

		zynqmp-gic-vcpu-alias@0xf9067000 {
			compatible = "qemu:memory-region";
			alias = < 0x06 0x03 >;
			reg = < 0x00 0xf9067000 0x1000 0x01 >;
		};

		zynqmp-gic-vcpu-alias@0xf9068000 {
			compatible = "qemu:memory-region";
			alias = < 0x06 0x03 >;
			reg = < 0x00 0xf9068000 0x1000 0x01 >;
		};

		zynqmp-gic-vcpu-alias@0xf9069000 {
			compatible = "qemu:memory-region";
			alias = < 0x06 0x03 >;
			reg = < 0x00 0xf9069000 0x1000 0x01 >;
		};

		zynqmp-gic-vcpu-alias@0xf906a000 {
			compatible = "qemu:memory-region";
			alias = < 0x06 0x03 >;
			reg = < 0x00 0xf906a000 0x1000 0x01 >;
		};

		zynqmp-gic-vcpu-alias@0xf906b000 {
			compatible = "qemu:memory-region";
			alias = < 0x06 0x03 >;
			reg = < 0x00 0xf906b000 0x1000 0x01 >;
		};

		zynqmp-gic-vcpu-alias@0xf906c000 {
			compatible = "qemu:memory-region";
			alias = < 0x06 0x03 >;
			reg = < 0x00 0xf906c000 0x1000 0x01 >;
		};

		zynqmp-gic-vcpu-alias@0xf906d000 {
			compatible = "qemu:memory-region";
			alias = < 0x06 0x03 >;
			reg = < 0x00 0xf906d000 0x1000 0x01 >;
		};

		zynqmp-gic-vcpu-alias@0xf906e000 {
			compatible = "qemu:memory-region";
			alias = < 0x06 0x03 >;
			reg = < 0x00 0xf906e000 0x1000 0x01 >;
		};

		zynqmp-gic-vcpu-alias@0xf906f000 {
			compatible = "qemu:memory-region";
			alias = < 0x06 0x03 >;
			reg = < 0x00 0xf906f000 0x1000 0x01 >;
		};
	};

	amba_rpu: amba_rpu@0 {
		#address-cells = < 0x02 >;
		#size-cells = < 0x02 >;
		#priority-cells = < 0x01 >;
		compatible = "xlnx,ps7-axi-interconnect-1.00.a", "simple-bus";
		ranges;
		phandle = < 0x33 >;

		rpu_intc_redirect_0: rpu_intc_redirect0@0 {
			#interrupt-cells = < 0x01 >;
			compatible = "xlnx,zynqmp-intc-redirect";
			interrupt-controller;
			interrupts-extended = < 0x7b 0x00 >;
			gpios = < 0x15 0x05 0x00 0x71 0x03 >;
			phandle = < 0x81 >;
		};

		rpu_intc_redirect_1: rpu_intc_redirect1@1 {
			#interrupt-cells = < 0x01 >;
			compatible = "xlnx,zynqmp-intc-redirect";
			interrupt-controller;
			interrupts-extended = < 0x7c 0x00 >;
			gpios = < 0x15 0x06 0x00 0x71 0x04 >;
			phandle = < 0x82 >;
		};

		tcm_mem_ctrl_0_A: tcm_mem_ctrl_A0@0 {
			compatible = "qemu,memory-controller";
			mr = < 0x7d >;
			gpios = < 0x16 0x18 0x16 0x14 >;
			gpio-names = "hlt_cntrl", "pwr_cntrl";
		};

		tcm_mem_ctrl_0_B: tcm_mem_ctrl_B0@0 {
			compatible = "qemu,memory-controller";
			mr = < 0x7e >;
			gpios = < 0x16 0x19 0x16 0x15 >;
			gpio-names = "hlt_cntrl", "pwr_cntrl";
		};

		tcm_mem_ctrl_1_A: tcm_mem_ctrl_A1@1 {
			compatible = "qemu,memory-controller";
			mr = < 0x7f >;
			gpios = < 0x16 0x1a 0x16 0x16 >;
			gpio-names = "hlt_cntrl", "pwr_cntrl";
		};

		tcm_mem_ctrl_1_B: tcm_mem_ctrl_B1@1 {
			compatible = "qemu,memory-controller";
			mr = < 0x80 >;
			gpios = < 0x16 0x1b 0x16 0x17 >;
			gpio-names = "hlt_cntrl", "pwr_cntrl";
		};

		rpu_gic: interrupt-controller@0xF9000000 {
			#address-cells = < 0x00 >;
			#interrupt-cells = < 0x03 >;
			#size-cells = < 0x00 >;
			compatible = "xlnx,zynqmp-scugic", "arm,gic";
			reg = < 0x00 0xf9000000 0x00 0x1000 0x00 0x00 0xf9001000 0x00 0x100 0x00 >;
			status = "disabled";
			interrupt-controller;
			num-irq = < 0x100 >;
			num-cpu = < 0x02 >;
			interrupts-extended = < 0x81 0x00 >, < 0x82 0x00 >;
			phandle = < 0x07 >;
		};

		ddr_memory_2_for_rpu: ddr_memory_2_for_rpu {
			compatible = "qemu:memory-region";
			alias = < 0x83 >;
			reg = < 0x00 0x30000 0x00 0x10000 0x00 >;
			phandle = < 0x12 >;
		};

		main_bus_for_rpu {
			compatible = "qemu:memory-region";
			alias = < 0x24 >;
			reg = < 0x00 0x00 0xffffffff 0xffffffff 0xffffffff >;
		};
	};

	smmu_tbu0: tbu0_slave@0 {
		#address-cells = < 0x02 >;
		#size-cells = < 0x02 >;
		compatible = "simple-bus";
		ranges;
		phandle = < 0x25 >;
	};

	smmu_tbu1: tbu1_slave@0 {
		#address-cells = < 0x02 >;
		#size-cells = < 0x02 >;
		compatible = "simple-bus";
		ranges;
		phandle = < 0x26 >;
	};

	smmu_tbu2: tbu2_slave@0 {
		#address-cells = < 0x02 >;
		#size-cells = < 0x02 >;
		compatible = "simple-bus";
		ranges;
		phandle = < 0x27 >;
	};

	smmu_tbu3: tbu3_slave@0 {
		#address-cells = < 0x02 >;
		#size-cells = < 0x02 >;
		compatible = "simple-bus";
		ranges;
		phandle = < 0x28 >;
	};

	smmu_tbu4: tbu4_slave@0 {
		#address-cells = < 0x02 >;
		#size-cells = < 0x02 >;
		compatible = "simple-bus";
		ranges;
		phandle = < 0x29 >;
	};

	smmu_tbu5: tbu5_slave@0 {
		#address-cells = < 0x02 >;
		#size-cells = < 0x02 >;
		compatible = "simple-bus";
		ranges;
		phandle = < 0x2a >;
	};

	tbu3_master: tbu3_master@0 {
		#address-cells = < 0x02 >;
		#size-cells = < 0x02 >;
		#priority-cells = < 0x01 >;
		compatible = "simple-bus";
		ranges;
		phandle = < 0x2d >;

		main_bus_for_tbu3 {
			compatible = "qemu:memory-region";
			alias = < 0x24 >;
			reg = < 0x00 0x00 0xffffffff 0xffffffff 0xffffffff >;
		};
	};

	tbu4_master: tbu4_master@0 {
		#address-cells = < 0x02 >;
		#size-cells = < 0x02 >;
		#priority-cells = < 0x01 >;
		compatible = "simple-bus";
		ranges;
		phandle = < 0x2e >;

		main_bus_for_tbu4 {
			compatible = "qemu:memory-region";
			alias = < 0x24 >;
			reg = < 0x00 0x00 0xffffffff 0xffffffff 0xffffffff >;
		};
	};

	tbu5_master: tbu5_master@0 {
		#address-cells = < 0x02 >;
		#size-cells = < 0x02 >;
		#priority-cells = < 0x01 >;
		compatible = "simple-bus";
		ranges;
		phandle = < 0x2f >;

		main_bus_for_tbu5 {
			compatible = "qemu:memory-region";
			alias = < 0x24 >;
			reg = < 0x00 0x00 0xffffffff 0xffffffff 0xffffffff >;
		};
	};

	cci_slave: cci_slave@0 {
		#address-cells = < 0x02 >;
		#size-cells = < 0x02 >;
		#priority-cells = < 0x01 >;
		compatible = "simple-bus";
		ranges;
		phandle = < 0x2c >;

		downstream {
			compatible = "qemu:memory-region";
			alias = < 0x24 >;
			reg = < 0x00 0x00 0xffffffff 0xffffffff 0x01 >;
		};
	};

	amba_prio: amba_prio@0 {
		#address-cells = < 0x02 >;
		#size-cells = < 0x02 >;
		#priority-cells = < 0x01 >;
		compatible = "qemu:memory-region";
		phandle = < 0x35 >;

		zynqmp_csu_stream_switch: csu_stream_switch@ffcc0200 {
			compatible = "zynqmp,csu-sss";
			reg = < 0x00 0xffca0008 0x00 0x04 0x00 >;
			stream-connected-dma = < 0x84 >;
			stream-connected-pcap = < 0x85 >;
			phandle = < 0x5e >;
		};

		zynqmp_csu_pcap: csu_pcap@nowhere {
			compatible = "zynqmp,csu-pcap";
			reg = < 0x00 0xffca3000 0x00 0x10000 0x00 >;
			stream-connected-pcap = < 0x5e >;
			phandle = < 0x85 >;
		};

		loader_write_0xFD0807E0: loader_write_cpu0_0x1003F@0xFD0807E0 {
			compatible = "loader";
			addr = < 0xfd0807e0 >;
			data = < 0x1003f >;
			data-len = < 0x04 >;
			cpu-num = < 0x00 >;
			attrs-debug = < 0x01 >;
			attrs-secure = < 0x00 >;
			attrs-requester-id = < 0x00 >;
		};

		loader_write_0xFD0809E0: loader_write_cpu0_0x1003F@0xFD0809E0 {
			compatible = "loader";
			addr = < 0xfd0809e0 >;
			data = < 0x1003f >;
			data-len = < 0x04 >;
			cpu-num = < 0x00 >;
			attrs-debug = < 0x01 >;
			attrs-secure = < 0x00 >;
			attrs-requester-id = < 0x00 >;
		};

		loader_write_0xFD080BE0: loader_write_cpu0_0x1003F@0xFD080BE0 {
			compatible = "loader";
			addr = < 0xfd080be0 >;
			data = < 0x1003f >;
			data-len = < 0x04 >;
			cpu-num = < 0x00 >;
			attrs-debug = < 0x01 >;
			attrs-secure = < 0x00 >;
			attrs-requester-id = < 0x00 >;
		};

		loader_write_0xFD080DE0: loader_write_cpu0_0x1003F@0xFD080DE0 {
			compatible = "loader";
			addr = < 0xfd080de0 >;
			data = < 0x1003f >;
			data-len = < 0x04 >;
			cpu-num = < 0x00 >;
			attrs-debug = < 0x01 >;
			attrs-secure = < 0x00 >;
			attrs-requester-id = < 0x00 >;
		};
	};

	misc_clk: misc_clk {
		#clock-cells = < 0x00 >;
		clock-frequency = < 0x2faf080 >;
		compatible = "fixed-clock";
		phandle = < 0x43 >;
	};

	pcie_ingress: pcie_ingress@0 {
		#address-cells = < 0x02 >;
		#size-cells = < 0x02 >;
		#priority-cells = < 0x01 >;
		compatible = "simple-bus";
		phandle = < 0x5a >;

		downstream {
			compatible = "qemu:memory-region";
			alias = < 0x26 >;
			reg = < 0x00 0x00 0xffffffff 0xffffffff 0xffffffff >;
		};
	};

	pcie_overlay: pcie_overlay@0 {
		#address-cells = < 0x02 >;
		#size-cells = < 0x02 >;
		#priority-cells = < 0x01 >;
		priority = < 0x02 >;
		compatible = "qemu:memory-region";
		container = < 0x23 >;
		phandle = < 0x5b >;
	};

	ddr_alias: ddr_alias@0 {
		compatible = "qemu:memory-region";
		container = < 0x86 >;
		alias = < 0x01 >;
		reg = < 0x00 0x00 0xffffffff 0xffffffff 0x00 >;
	};

	qemu_sysmem: qemu_sysmem@0 {
		#address-cells = < 0x02 >;
		#size-cells = < 0x02 >;
		#priority-cells = < 0x01 >;
		compatible = "qemu:system-memory";
		phandle = < 0x86 >;
	};

	pmu_memattr: pmu_ma {
		compatible = "qemu:memory-transaction-attr";
		secure = < 0x01 >;
		requester-id = < 0x40 >;
	};

	apu0_s_memattr: apu0_s_ma {
		compatible = "qemu:memory-transaction-attr";
		secure = < 0x01 >;
		requester-id = < 0x80 >;
		phandle = < 0x68 >;
	};

	apu0_ns_memattr: apu0_ns_ma {
		compatible = "qemu:memory-transaction-attr";
		secure = < 0x00 >;
		requester-id = < 0x80 >;
		phandle = < 0x69 >;
	};

	apu1_s_memattr: apu1_s_ma {
		compatible = "qemu:memory-transaction-attr";
		secure = < 0x01 >;
		requester-id = < 0x8d >;
		phandle = < 0x6a >;
	};

	apu1_ns_memattr: apu1_ns_ma {
		compatible = "qemu:memory-transaction-attr";
		secure = < 0x00 >;
		requester-id = < 0x8d >;
		phandle = < 0x6b >;
	};

	apu2_s_memattr: apu2_s_ma {
		compatible = "qemu:memory-transaction-attr";
		secure = < 0x01 >;
		requester-id = < 0x8e >;
		phandle = < 0x6c >;
	};

	apu2_ns_memattr: apu2_ns_ma {
		compatible = "qemu:memory-transaction-attr";
		secure = < 0x00 >;
		requester-id = < 0x8e >;
		phandle = < 0x6d >;
	};

	apu3_s_memattr: apu3_s_ma {
		compatible = "qemu:memory-transaction-attr";
		secure = < 0x01 >;
		requester-id = < 0x8f >;
		phandle = < 0x6e >;
	};

	apu3_ns_memattr: apu3_ns_ma {
		compatible = "qemu:memory-transaction-attr";
		secure = < 0x00 >;
		requester-id = < 0x8f >;
		phandle = < 0x6f >;
	};

	rpu0_memattr: rpu0_ma {
		compatible = "qemu:memory-transaction-attr";
		secure = < 0x01 >;
		requester-id = < 0x2e >;
		phandle = < 0x72 >;
	};

	rpu1_memattr: rpu1_ma {
		compatible = "qemu:memory-transaction-attr";
		secure = < 0x01 >;
		requester-id = < 0x2f >;
		phandle = < 0x74 >;
	};

	gem0_memattr: gem0_ma {
		compatible = "qemu:memory-transaction-attr";
		secure = < 0x00 >;
		requester-id = < 0x874 >;
		phandle = < 0x44 >;
	};

	gem1_memattr: gem1_ma {
		compatible = "qemu:memory-transaction-attr";
		secure = < 0x00 >;
		requester-id = < 0x875 >;
		phandle = < 0x45 >;
	};

	gem2_memattr: gem2_ma {
		compatible = "qemu:memory-transaction-attr";
		secure = < 0x00 >;
		requester-id = < 0x876 >;
		phandle = < 0x46 >;
	};

	gem3_memattr: gem3_ma {
		compatible = "qemu:memory-transaction-attr";
		secure = < 0x00 >;
		requester-id = < 0x877 >;
		phandle = < 0x47 >;
	};

	qspi_dma_memattr: qspi_dma_ma {
		compatible = "qemu:memory-transaction-attr";
		secure = < 0x00 >;
		requester-id = < 0x873 >;
		phandle = < 0x49 >;
	};

	pcie_ns_memattr: pcie_ns_ma {
		compatible = "qemu:memory-transaction-attr";
		secure = < 0x00 >;
		requester-id = < 0x4d0 >;
		phandle = < 0x5c >;
	};

	csu_dma_memattr: csu_dma_ma {
		compatible = "qemu:memory-transaction-attr";
		secure = < 0x00 >;
		requester-id = < 0x851 >;
		phandle = < 0x5d >;
	};

	protected_amba: protected_amba@0 {
		#address-cells = < 0x02 >;
		#size-cells = < 0x02 >;
		#priority-cells = < 0x01 >;
		compatible = "xlnx,ps7-axi-interconnect-1.00.a", "simple-bus";
		ranges;
		phandle = < 0x24 >;

		downstream {
			compatible = "qemu:memory-region";
			alias = < 0x23 >;
			reg = < 0x00 0x00 0xffffffff 0xffffffff 0xffffffff >;
		};
	};

	ddr3_ram: memory@00000000 {
		compatible = "qemu:memory-region";
		device_type = "memory";
		container = < 0x23 >;
		phandle = < 0x01 >;
	};

	pmu_ram: pmu_ram@ffdc0000 {
		compatible = "qemu:memory-region";
		container = < 0x23 >;
		qemu,ram = < 0x02 >;
		reg = < 0x00 0xffdc0000 0x20000 >;
	};

	tcm_ram_r5_0_A: tcm_ram_r5_0_A@0x00000 {
		compatible = "qemu:memory-region";
		container = < 0x5f >;
		qemu,ram = < 0x02 >;
		reg = < 0x00 0x00 0x10000 >;
		phandle = < 0x7d >;
	};

	tcm_ram_r5_0_B: tcm_ram_r5_0_B@0x20000 {
		compatible = "qemu:memory-region";
		container = < 0x5f >;
		qemu,ram = < 0x02 >;
		reg = < 0x00 0x20000 0x10000 >;
		phandle = < 0x7e >;
	};

	tcm_ram_r5_1_A: tcm_ram_r5_1_A@0x00000 {
		compatible = "qemu:memory-region";
		container = < 0x60 >;
		qemu,ram = < 0x02 >;
		reg = < 0x00 0x00 0x10000 >;
		phandle = < 0x7f >;
	};

	tcm_ram_r5_1_B: tcm_ram_r5_1_B@0x20000 {
		compatible = "qemu:memory-region";
		container = < 0x60 >;
		qemu,ram = < 0x02 >;
		reg = < 0x00 0x20000 0x10000 >;
		phandle = < 0x80 >;
	};

	icache_rpu0: icache_rpu0@0x40000 {
		compatible = "qemu:memory-region";
		container = < 0x5f >;
		qemu,ram = < 0x02 >;
		reg = < 0x00 0x40000 0x8000 >;
	};

	dcache_rpu0: dcache_rpu0@0x50000 {
		compatible = "qemu:memory-region";
		container = < 0x5f >;
		qemu,ram = < 0x02 >;
		reg = < 0x00 0x50000 0x8000 >;
	};

	icache_rpu1: icache_rpu1@0x30000 {
		compatible = "qemu:memory-region";
		container = < 0x60 >;
		qemu,ram = < 0x02 >;
		reg = < 0x00 0x30000 0x8000 >;
		phandle = < 0x10 >;
	};

	dcache_rpu1: dcache_rpu1@0x40000 {
		compatible = "qemu:memory-region";
		container = < 0x60 >;
		qemu,ram = < 0x02 >;
		reg = < 0x00 0x40000 0x8000 >;
		phandle = < 0x11 >;
	};

	ipibuf_ram: ipibuf@ff990000 {
		compatible = "qemu:memory-region";
		container = < 0x23 >;
		qemu,ram = < 0x02 >;
		reg = < 0x00 0xff990000 0x1000 >;
	};

	ocm_ram: ocm_ram@0 {
		compatible = "qemu:memory-region";
		phandle = < 0x32 >;
	};

	ocm_ram_bank_0: ocm_ram_bank_0@0x00000 {
		compatible = "qemu:memory-region";
		container = < 0x32 >;
		qemu,ram = < 0x02 >;
		reg = < 0x00 0x00 0x10000 >;
		phandle = < 0x4e >;
	};

	ocm_ram_bank_1: ocm_ram_bank_1@0x10000 {
		compatible = "qemu:memory-region";
		container = < 0x32 >;
		qemu,ram = < 0x02 >;
		reg = < 0x00 0x10000 0x10000 >;
		phandle = < 0x4f >;
	};

	ocm_ram_bank_2: ocm_ram_bank_2@0x20000 {
		compatible = "qemu:memory-region";
		container = < 0x32 >;
		qemu,ram = < 0x02 >;
		reg = < 0x00 0x20000 0x10000 >;
		phandle = < 0x50 >;
	};

	ocm_ram_bank_3: ocm_ram_bank_3@0x30000 {
		compatible = "qemu:memory-region";
		container = < 0x32 >;
		qemu,ram = < 0x02 >;
		reg = < 0x00 0x30000 0x10000 >;
		phandle = < 0x51 >;
	};

	tcm_cache_rpu0: tcm_cache_rpu0@0 {
		#address-cells = < 0x02 >;
		#size-cells = < 0x02 >;
		#priority-cells = < 0x01 >;
		compatible = "qemu:memory-region";
		phandle = < 0x5f >;

		atcm1_for_rpu0: atcm1_for_rpu0 {
			compatible = "qemu:memory-region";
			alias = < 0x7f >;
			reg = < 0x00 0x10000 0x00 0x10000 0x01 >;
			phandle = < 0x0e >;
		};

		btcm1_for_rpu0: btcm1_for_rpu0 {
			compatible = "qemu:memory-region";
			alias = < 0x80 >;
			reg = < 0x00 0x30000 0x00 0x10000 0x01 >;
			phandle = < 0x0f >;
		};
	};

	amba_rpu0: amba_rpu0@0 {
		#address-cells = < 0x02 >;
		#size-cells = < 0x02 >;
		#priority-cells = < 0x01 >;
		compatible = "xlnx,ps7-axi-interconnect-1.00.a", "simple-bus";
		ranges;
		phandle = < 0x70 >;

		tcm_cache_rpu0 {
			compatible = "qemu:memory-region";
			alias = < 0x5f >;
			reg = < 0x00 0x00 0xffffffff 0xffffffff 0x00 >;
		};

		rpu_bus_for_rpu0 {
			compatible = "qemu:memory-region";
			alias = < 0x33 >;
			reg = < 0x00 0x00 0xffffffff 0xffffffff 0xffffffff >;
		};
	};

	tcm_cache_rpu1: tcm_cache_rpu1@0 {
		#address-cells = < 0x02 >;
		#size-cells = < 0x02 >;
		#priority-cells = < 0x01 >;
		compatible = "qemu:memory-region";
		phandle = < 0x60 >;
	};

	amba_rpu1: amba_rpu1@0 {
		#address-cells = < 0x02 >;
		#size-cells = < 0x02 >;
		#priority-cells = < 0x01 >;
		compatible = "xlnx,ps7-axi-interconnect-1.00.a", "simple-bus";
		ranges;
		phandle = < 0x73 >;

		tcm_cache_rpu1 {
			compatible = "qemu:memory-region";
			alias = < 0x60 >;
			reg = < 0x00 0x00 0xffffffff 0xffffffff 0x01 >;
		};

		rpu_bus_for_rpu1 {
			compatible = "qemu:memory-region";
			alias = < 0x33 >;
			reg = < 0x00 0x00 0xffffffff 0xffffffff 0xffffffff >;
		};
	};

	amba_pl: amba_pl {
		#address-cells = < 0x02 >;
		#size-cells = < 0x02 >;
		compatible = "simple-bus";
		ranges;
		phandle = < 0x75 >;
	};

	mdio0: mdio {
		#address-cells = < 0x01 >;
		#size-cells = < 0x00 >;
		compatible = "mdio";
		phandle = < 0x48 >;

		phy0: phy@7 {
			compatible = "88e1118r";
			device_type = "ethernet-phy";
			reg = < 0x07 >;
		};

		phy1: phy@12 {
			compatible = "88e1118r";
			device_type = "ethernet-phy";
			reg = < 0x0c >;
		};
	};
};
